AUTOSAR XML (schema 4-2-2)
package /STELLANTIS/EPT/ASWCs
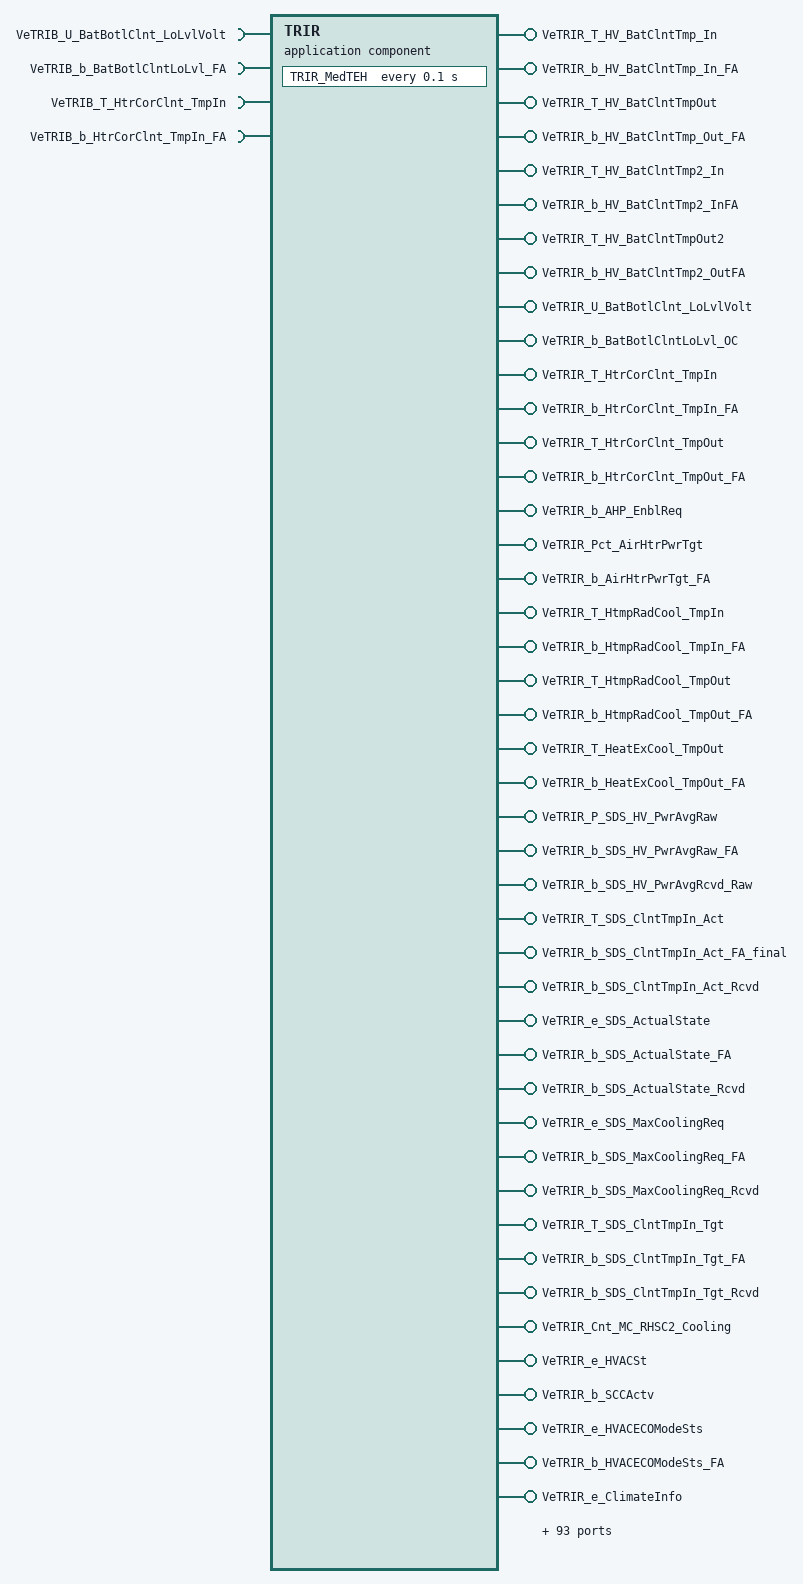
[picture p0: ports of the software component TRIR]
  application sw component type TRIR
    4 x require port, all with nonqueued-receiver-com-spec{data-element=Value, init-value=0}:
      VeTRIB_U_BatBotlClnt_LoLvlVolt: required-interface=VeTRIB_U_BatBotlClnt_LoLvlVolt
      VeTRIB_b_BatBotlClntLoLvl_FA: required-interface=VeTRIB_b_BatBotlClntLoLvl_FA
      VeTRIB_T_HtrCorClnt_TmpIn: required-interface=VeTRIB_T_HtrCorClnt_TmpIn
      VeTRIB_b_HtrCorClnt_TmpIn_FA: required-interface=VeTRIB_b_HtrCorClnt_TmpIn_FA
    137 x provide port:
      VeTRIR_T_HV_BatClntTmp_In: nonqueued-sender-com-spec{data-element=Value, init-value=0}, provided-interface=VeTRIR_T_HV_BatClntTmp_In
      VeTRIR_b_HV_BatClntTmp_In_FA: nonqueued-sender-com-spec{data-element=Value, init-value=0}, provided-interface=VeTRIR_b_HV_BatClntTmp_In_FA
      VeTRIR_T_HV_BatClntTmpOut: nonqueued-sender-com-spec{data-element=Value, init-value=0}, provided-interface=VeTRIR_T_HV_BatClntTmpOut
      VeTRIR_b_HV_BatClntTmp_Out_FA: nonqueued-sender-com-spec{data-element=Value, init-value=0}, provided-interface=VeTRIR_b_HV_BatClntTmp_Out_FA
      VeTRIR_T_HV_BatClntTmp2_In: nonqueued-sender-com-spec{data-element=Value, init-value=0}, provided-interface=VeTRIR_T_HV_BatClntTmp2_In
      VeTRIR_b_HV_BatClntTmp2_InFA: nonqueued-sender-com-spec{data-element=Value, init-value=0}, provided-interface=VeTRIR_b_HV_BatClntTmp2_InFA
      VeTRIR_T_HV_BatClntTmpOut2: nonqueued-sender-com-spec{data-element=Value, init-value=0}, provided-interface=VeTRIR_T_HV_BatClntTmpOut2
      VeTRIR_b_HV_BatClntTmp2_OutFA: nonqueued-sender-com-spec{data-element=Value, init-value=0}, provided-interface=VeTRIR_b_HV_BatClntTmp2_OutFA
      VeTRIR_U_BatBotlClnt_LoLvlVolt: nonqueued-sender-com-spec{data-element=Value, init-value=0}, provided-interface=VeTRIR_U_BatBotlClnt_LoLvlVolt
      VeTRIR_b_BatBotlClntLoLvl_OC: nonqueued-sender-com-spec{data-element=Value, init-value=0}, provided-interface=VeTRIR_b_BatBotlClntLoLvl_OC
      VeTRIR_T_HtrCorClnt_TmpIn: nonqueued-sender-com-spec{data-element=Value, init-value=0}, provided-interface=VeTRIR_T_HtrCorClnt_TmpIn
      VeTRIR_b_HtrCorClnt_TmpIn_FA: nonqueued-sender-com-spec{data-element=Value, init-value=0}, provided-interface=VeTRIR_b_HtrCorClnt_TmpIn_FA
      VeTRIR_T_HtrCorClnt_TmpOut: nonqueued-sender-com-spec{data-element=Value, init-value=0}, provided-interface=VeTRIR_T_HtrCorClnt_TmpOut
      VeTRIR_b_HtrCorClnt_TmpOut_FA: nonqueued-sender-com-spec{data-element=Value, init-value=0}, provided-interface=VeTRIR_b_HtrCorClnt_TmpOut_FA
      VeTRIR_b_AHP_EnblReq: nonqueued-sender-com-spec{data-element=Value, init-value=0}, provided-interface=VeTRIR_b_AHP_EnblReq
      VeTRIR_Pct_AirHtrPwrTgt: nonqueued-sender-com-spec{data-element=Value, init-value=0}, provided-interface=VeTRIR_Pct_AirHtrPwrTgt
      VeTRIR_b_AirHtrPwrTgt_FA: nonqueued-sender-com-spec{data-element=Value, init-value=0}, provided-interface=VeTRIR_b_AirHtrPwrTgt_FA
      VeTRIR_T_HtmpRadCool_TmpIn: nonqueued-sender-com-spec{data-element=Value, init-value=0}, provided-interface=VeTRIR_T_HtmpRadCool_TmpIn
      VeTRIR_b_HtmpRadCool_TmpIn_FA: nonqueued-sender-com-spec{data-element=Value, init-value=0}, provided-interface=VeTRIR_b_HtmpRadCool_TmpIn_FA
      VeTRIR_T_HtmpRadCool_TmpOut: nonqueued-sender-com-spec{data-element=Value, init-value=0}, provided-interface=VeTRIR_T_HtmpRadCool_TmpOut
      VeTRIR_b_HtmpRadCool_TmpOut_FA: nonqueued-sender-com-spec{data-element=Value, init-value=0}, provided-interface=VeTRIR_b_HtmpRadCool_TmpOut_FA
      VeTRIR_T_HeatExCool_TmpOut: nonqueued-sender-com-spec{data-element=Value, init-value=0}, provided-interface=VeTRIR_T_HeatExCool_TmpOut
      VeTRIR_b_HeatExCool_TmpOut_FA: nonqueued-sender-com-spec{data-element=Value, init-value=0}, provided-interface=VeTRIR_b_HeatExCool_TmpOut_FA
      VeTRIR_P_SDS_HV_PwrAvgRaw: nonqueued-sender-com-spec{data-element=Value, init-value=0}, provided-interface=VeTRIR_P_SDS_HV_PwrAvgRaw
      VeTRIR_b_SDS_HV_PwrAvgRaw_FA: nonqueued-sender-com-spec{data-element=Value, init-value=0}, provided-interface=VeTRIR_b_SDS_HV_PwrAvgRaw_FA
      VeTRIR_b_SDS_HV_PwrAvgRcvd_Raw: nonqueued-sender-com-spec{data-element=Value, init-value=0}, provided-interface=VeTRIR_b_SDS_HV_PwrAvgRcvd_Raw
      VeTRIR_T_SDS_ClntTmpIn_Act: nonqueued-sender-com-spec{data-element=Value, init-value=0}, provided-interface=VeTRIR_T_SDS_ClntTmpIn_Act
      VeTRIR_b_SDS_ClntTmpIn_Act_FA_final: nonqueued-sender-com-spec{data-element=Value, init-value=0}, provided-interface=VeTRIR_b_SDS_ClntTmpIn_Act_FA_final
      VeTRIR_b_SDS_ClntTmpIn_Act_Rcvd: nonqueued-sender-com-spec{data-element=Value, init-value=0}, provided-interface=VeTRIR_b_SDS_ClntTmpIn_Act_Rcvd
      VeTRIR_e_SDS_ActualState: nonqueued-sender-com-spec{data-element=Value, init-value=CeTRIR_e_SDS_OFF}, provided-interface=VeTRIR_e_SDS_ActualState
      VeTRIR_b_SDS_ActualState_FA: nonqueued-sender-com-spec{data-element=Value, init-value=0}, provided-interface=VeTRIR_b_SDS_ActualState_FA
      VeTRIR_b_SDS_ActualState_Rcvd: nonqueued-sender-com-spec{data-element=Value, init-value=0}, provided-interface=VeTRIR_b_SDS_ActualState_Rcvd
      VeTRIR_e_SDS_MaxCoolingReq: nonqueued-sender-com-spec{data-element=Value, init-value=CeTRIR_e_HCP_MaxCoolingNotRequested}, provided-interface=VeTRIR_e_SDS_MaxCoolingReq
      VeTRIR_b_SDS_MaxCoolingReq_FA: nonqueued-sender-com-spec{data-element=Value, init-value=0}, provided-interface=VeTRIR_b_SDS_MaxCoolingReq_FA
      VeTRIR_b_SDS_MaxCoolingReq_Rcvd: nonqueued-sender-com-spec{data-element=Value, init-value=0}, provided-interface=VeTRIR_b_SDS_MaxCoolingReq_Rcvd
      VeTRIR_T_SDS_ClntTmpIn_Tgt: nonqueued-sender-com-spec{data-element=Value, init-value=0}, provided-interface=VeTRIR_T_SDS_ClntTmpIn_Tgt
      VeTRIR_b_SDS_ClntTmpIn_Tgt_FA: nonqueued-sender-com-spec{data-element=Value, init-value=0}, provided-interface=VeTRIR_b_SDS_ClntTmpIn_Tgt_FA
      VeTRIR_b_SDS_ClntTmpIn_Tgt_Rcvd: nonqueued-sender-com-spec{data-element=Value, init-value=0}, provided-interface=VeTRIR_b_SDS_ClntTmpIn_Tgt_Rcvd
      VeTRIR_Cnt_MC_RHSC2_Cooling: nonqueued-sender-com-spec{data-element=Value, init-value=0}, provided-interface=VeTRIR_Cnt_MC_RHSC2_Cooling
      VeTRIR_e_HVACSt: nonqueued-sender-com-spec{data-element=Value, init-value=CeTRIR_e_HVAC_Off}, provided-interface=VeTRIR_e_HVACSt
      VeTRIR_b_SCCActv: nonqueued-sender-com-spec{data-element=Value, init-value=0}, provided-interface=VeTRIR_b_SCCActv
      VeTRIR_e_HVACECOModeSts: nonqueued-sender-com-spec{data-element=Value, init-value=CeTRIR_e_HVAC_ECO_OFF}, provided-interface=VeTRIR_e_HVACECOModeSts
      VeTRIR_b_HVACECOModeSts_FA: nonqueued-sender-com-spec{data-element=Value, init-value=0}, provided-interface=VeTRIR_b_HVACECOModeSts_FA
      VeTRIR_e_ClimateInfo: nonqueued-sender-com-spec{data-element=Value, init-value=CeTRIR_e_SPST_ON}, provided-interface=VeTRIR_e_ClimateInfo
      VeTRIR_b_ClimateInfo_FA: nonqueued-sender-com-spec{data-element=Value, init-value=0}, provided-interface=VeTRIR_b_ClimateInfo_FA
      VeTRIR_b_KeepHotColdButtonStatus: nonqueued-sender-com-spec{data-element=Value, init-value=0}, provided-interface=VeTRIR_b_KeepHotColdButtonStatus
      VeTRIR_b_KeepHotColdButtonStatus_FA: nonqueued-sender-com-spec{data-element=Value, init-value=0}, provided-interface=VeTRIR_b_KeepHotColdButtonStatus_FA
      VeTRIR_b_Comfort_EnblAct: nonqueued-sender-com-spec{data-element=Value, init-value=0}, provided-interface=VeTRIR_b_Comfort_EnblAct
      VeTRIR_b_Comfort_EnblAct_FA: nonqueued-sender-com-spec{data-element=Value, init-value=0}, provided-interface=VeTRIR_b_Comfort_EnblAct_FA
      VeTRIR_b_TrunkStatus: nonqueued-sender-com-spec{data-element=Value, init-value=0}, provided-interface=VeTRIR_b_TrunkStatus
      VeTRIR_b_TrunkStatus_FA: nonqueued-sender-com-spec{data-element=Value, init-value=0}, provided-interface=VeTRIR_b_TrunkStatus_FA
      VeTRIR_b_LoadShed: nonqueued-sender-com-spec{data-element=Value, init-value=0}, provided-interface=VeTRIR_b_LoadShed
      VeTRIR_b_LoadShed_FA: nonqueued-sender-com-spec{data-element=Value, init-value=0}, provided-interface=VeTRIR_b_LoadShed_FA
      VeTRIR_e_HSW_Sts: nonqueued-sender-com-spec{data-element=Value, init-value=CeTRIR_e_ModeOFF}, provided-interface=VeTRIR_e_HSW_Sts
      VeTRIR_b_HSW_Sts_FA: nonqueued-sender-com-spec{data-element=Value, init-value=0}, provided-interface=VeTRIR_b_HSW_Sts_FA
      VeTRIR_b_HSW_Fail: nonqueued-sender-com-spec{data-element=Value, init-value=0}, provided-interface=VeTRIR_b_HSW_Fail
      VeTRIR_e_FL_HS_Sts: nonqueued-sender-com-spec{data-element=Value, init-value=CeTRIR_e_ModeOFF}, provided-interface=VeTRIR_e_FL_HS_Sts
      VeTRIR_b_FL_HS_Fail: nonqueued-sender-com-spec{data-element=Value, init-value=0}, provided-interface=VeTRIR_b_FL_HS_Fail
      VeTRIR_e_FR_HS_Sts: nonqueued-sender-com-spec{data-element=Value, init-value=CeTRIR_e_ModeOFF}, provided-interface=VeTRIR_e_FR_HS_Sts
      VeTRIR_b_FR_HS_Fail: nonqueued-sender-com-spec{data-element=Value, init-value=0}, provided-interface=VeTRIR_b_FR_HS_Fail
      VeTRIR_e_RL_HS_Sts: nonqueued-sender-com-spec{data-element=Value, init-value=CeTRIR_e_ModeOFF}, provided-interface=VeTRIR_e_RL_HS_Sts
      VeTRIR_b_RL_HS_Fail: nonqueued-sender-com-spec{data-element=Value, init-value=0}, provided-interface=VeTRIR_b_RL_HS_Fail
      VeTRIR_e_RR_HS_Sts: nonqueued-sender-com-spec{data-element=Value, init-value=CeTRIR_e_ModeOFF}, provided-interface=VeTRIR_e_RR_HS_Sts
      VeTRIR_b_RR_HS_Fail: nonqueued-sender-com-spec{data-element=Value, init-value=0}, provided-interface=VeTRIR_b_RR_HS_Fail
      VeTRIR_e_FL_VS_Sts: nonqueued-sender-com-spec{data-element=Value, init-value=CeTRIR_e_ModeOFF}, provided-interface=VeTRIR_e_FL_VS_Sts
      VeTRIR_b_FL_VS_Fail: nonqueued-sender-com-spec{data-element=Value, init-value=0}, provided-interface=VeTRIR_b_FL_VS_Fail
      VeTRIR_e_FR_VS_Sts: nonqueued-sender-com-spec{data-element=Value, init-value=CeTRIR_e_ModeOFF}, provided-interface=VeTRIR_e_FR_VS_Sts
      VeTRIR_b_FR_VS_Fail: nonqueued-sender-com-spec{data-element=Value, init-value=0}, provided-interface=VeTRIR_b_FR_VS_Fail
      VeTRIR_e_RL_VS_Sts: nonqueued-sender-com-spec{data-element=Value, init-value=CeTRIR_e_ModeOFF}, provided-interface=VeTRIR_e_RL_VS_Sts
      VeTRIR_b_RL_VS_Fail: nonqueued-sender-com-spec{data-element=Value, init-value=0}, provided-interface=VeTRIR_b_RL_VS_Fail
      VeTRIR_e_RR_VS_Sts: nonqueued-sender-com-spec{data-element=Value, init-value=CeTRIR_e_ModeOFF}, provided-interface=VeTRIR_e_RR_VS_Sts
      VeTRIR_b_RR_VS_Fail: nonqueued-sender-com-spec{data-element=Value, init-value=0}, provided-interface=VeTRIR_b_RR_VS_Fail
      FsftTRIR_Pct_AirHtwPwrTgt: server-com-spec=FsftTRIR_Pct_AirHtwPwrTgt, provided-interface=FsftTRIR_Pct_AirHtwPwrTgt
      FsftTRIR_T_HV_BatClntTmp2Out: server-com-spec=FsftTRIR_T_HV_BatClntTmp2Out, provided-interface=FsftTRIR_T_HV_BatClntTmp2Out
      FsftTRIR_T_HV_BatClntTmp2_In: server-com-spec=FsftTRIR_T_HV_BatClntTmp2_In, provided-interface=FsftTRIR_T_HV_BatClntTmp2_In
      FsftTRIR_T_HV_BatClntTmpOut: server-com-spec=FsftTRIR_T_HV_BatClntTmpOut, provided-interface=FsftTRIR_T_HV_BatClntTmpOut
      FsftTRIR_T_HV_BatClntTmp_In: server-com-spec=FsftTRIR_T_HV_BatClntTmp_In, provided-interface=FsftTRIR_T_HV_BatClntTmp_In
      FsftTRIR_T_SDS_ClntTmpIn_Act: server-com-spec=FsftTRIR_T_SDS_ClntTmpIn_Act, provided-interface=FsftTRIR_T_SDS_ClntTmpIn_Act
      FsftTRIR_b_AHP_EnblReq: server-com-spec=FsftTRIR_b_AHP_EnblReq, provided-interface=FsftTRIR_b_AHP_EnblReq
      FsftTRIR_b_BCM_Comfort_EnblAct: server-com-spec=FsftTRIR_b_BCM_Comfort_EnblAct, provided-interface=FsftTRIR_b_BCM_Comfort_EnblAct
      FsftTRIR_b_ClimateInfo: server-com-spec=FsftTRIR_b_ClimateInfo, provided-interface=FsftTRIR_b_ClimateInfo
      FsftTRIR_b_ETM_KeepHotColdButtonStatus: server-com-spec=FsftTRIR_b_ETM_KeepHotColdButtonStatus, provided-interface=FsftTRIR_b_ETM_KeepHotColdButtonStatus
      FsftTRIR_b_HSW_Sts: server-com-spec=FsftTRIR_b_HSW_Sts, provided-interface=FsftTRIR_b_HSW_Sts
      FsftTRIR_b_HVACECOModeSts: server-com-spec=FsftTRIR_b_HVACECOModeSts, provided-interface=FsftTRIR_b_HVACECOModeSts
      FsftTRIR_b_HVACPrecCondSts: server-com-spec=FsftTRIR_b_HVACPrecCondSts, provided-interface=FsftTRIR_b_HVACPrecCondSts
      FsftTRIR_b_HeatExCool_TmpOut: server-com-spec=FsftTRIR_b_HeatExCool_TmpOut, provided-interface=FsftTRIR_b_HeatExCool_TmpOut
      FsftTRIR_b_HtmpRadCool_TmpIn: server-com-spec=FsftTRIR_b_HtmpRadCool_TmpIn, provided-interface=FsftTRIR_b_HtmpRadCool_TmpIn
      FsftTRIR_b_HtmpRadCool_TmpOut: server-com-spec=FsftTRIR_b_HtmpRadCool_TmpOut, provided-interface=FsftTRIR_b_HtmpRadCool_TmpOut
      FsftTRIR_b_HtrCorClnt_TmpOut: server-com-spec=FsftTRIR_b_HtrCorClnt_TmpOut, provided-interface=FsftTRIR_b_HtrCorClnt_TmpOut
      FsftTRIR_b_LoadShed: server-com-spec=FsftTRIR_b_LoadShed, provided-interface=FsftTRIR_b_LoadShed
      FsftTRIR_b_SCCActv: server-com-spec=FsftTRIR_b_SCCActv, provided-interface=FsftTRIR_b_SCCActv
      FsftTRIR_b_TrunkStatus: server-com-spec=FsftTRIR_b_TrunkStatus, provided-interface=FsftTRIR_b_TrunkStatus
      PokeTRIR_Cnt_MC_RHSC2_Cooling: server-com-spec{operation=PokeTRIR_Cnt_MC_RHSC2_Cooling, queue-length=1}, provided-interface=PokeTRIR_Cnt_MC_RHSC2_Cooling
      PokeTRIR_P_SDS_HV_PwrAvg: server-com-spec{operation=PokeTRIR_P_SDS_HV_PwrAvg, queue-length=1}, provided-interface=PokeTRIR_P_SDS_HV_PwrAvg
      PokeTRIR_Pct_AirHtwPwrTgt: server-com-spec{operation=PokeTRIR_Pct_AirHtwPwrTgt, queue-length=1}, provided-interface=PokeTRIR_Pct_AirHtwPwrTgt
      PokeTRIR_T_HV_BatClntTmp2_In: server-com-spec{operation=PokeTRIR_T_HV_BatClntTmp2_In, queue-length=1}, provided-interface=PokeTRIR_T_HV_BatClntTmp2_In
      PokeTRIR_T_HV_BatClntTmp2_Out: server-com-spec{operation=PokeTRIR_T_HV_BatClntTmp2_Out, queue-length=1}, provided-interface=PokeTRIR_T_HV_BatClntTmp2_Out
      PokeTRIR_T_HV_BatClntTmp_In: server-com-spec{operation=PokeTRIR_T_HV_BatClntTmp_In, queue-length=1}, provided-interface=PokeTRIR_T_HV_BatClntTmp_In
      PokeTRIR_T_HV_BatClntTmp_Out: server-com-spec{operation=PokeTRIR_T_HV_BatClntTmp_Out, queue-length=1}, provided-interface=PokeTRIR_T_HV_BatClntTmp_Out
      PokeTRIR_T_HeatExCool_TmpOut: server-com-spec{operation=PokeTRIR_T_HeatExCool_TmpOut, queue-length=1}, provided-interface=PokeTRIR_T_HeatExCool_TmpOut
      PokeTRIR_T_HtmpRadCool_TmpIn: server-com-spec{operation=PokeTRIR_T_HtmpRadCool_TmpIn, queue-length=1}, provided-interface=PokeTRIR_T_HtmpRadCool_TmpIn
      PokeTRIR_T_HtmpRadCool_TmpOut: server-com-spec{operation=PokeTRIR_T_HtmpRadCool_TmpOut, queue-length=1}, provided-interface=PokeTRIR_T_HtmpRadCool_TmpOut
      PokeTRIR_T_HtrCorClnt_TmpOut: server-com-spec{operation=PokeTRIR_T_HtrCorClnt_TmpOut, queue-length=1}, provided-interface=PokeTRIR_T_HtrCorClnt_TmpOut
      PokeTRIR_T_SDS_ClntTmpIn_Act: server-com-spec{operation=PokeTRIR_T_SDS_ClntTmpIn_Act, queue-length=1}, provided-interface=PokeTRIR_T_SDS_ClntTmpIn_Act
      PokeTRIR_T_SDS_ClntTmpIn_Tgt: server-com-spec{operation=PokeTRIR_T_SDS_ClntTmpIn_Tgt, queue-length=1}, provided-interface=PokeTRIR_T_SDS_ClntTmpIn_Tgt
      PokeTRIR_b_AHP_EnblReq: server-com-spec{operation=PokeTRIR_b_AHP_EnblReq, queue-length=1}, provided-interface=PokeTRIR_b_AHP_EnblReq
      PokeTRIR_b_BCM_Comfort_EnblAct: server-com-spec{operation=PokeTRIR_b_BCM_Comfort_EnblAct, queue-length=1}, provided-interface=PokeTRIR_b_BCM_Comfort_EnblAct
      PokeTRIR_b_ETM_KeepHotColdButtonStatus: server-com-spec{operation=PokeTRIR_b_ETM_KeepHotColdButtonStatus, queue-length=1}, provided-interface=PokeTRIR_b_ETM_KeepHotColdButtonStatus
      PokeTRIR_b_FL_HS_Fail: server-com-spec{operation=PokeTRIR_b_FL_HS_Fail, queue-length=1}, provided-interface=PokeTRIR_b_FL_HS_Fail
      PokeTRIR_b_FL_VS_Fail: server-com-spec{operation=PokeTRIR_b_FL_VS_Fail, queue-length=1}, provided-interface=PokeTRIR_b_FL_VS_Fail
      PokeTRIR_b_FR_HS_Fail: server-com-spec{operation=PokeTRIR_b_FR_HS_Fail, queue-length=1}, provided-interface=PokeTRIR_b_FR_HS_Fail
      PokeTRIR_b_FR_VS_Fail: server-com-spec{operation=PokeTRIR_b_FR_VS_Fail, queue-length=1}, provided-interface=PokeTRIR_b_FR_VS_Fail
      PokeTRIR_b_HSW_Fail: server-com-spec{operation=PokeTRIR_b_HSW_Fail, queue-length=1}, provided-interface=PokeTRIR_b_HSW_Fail
      PokeTRIR_b_LoadShed: server-com-spec{operation=PokeTRIR_b_LoadShed, queue-length=1}, provided-interface=PokeTRIR_b_LoadShed
      PokeTRIR_b_RL_HS_Fail: server-com-spec{operation=PokeTRIR_b_RL_HS_Fail, queue-length=1}, provided-interface=PokeTRIR_b_RL_HS_Fail
      PokeTRIR_b_RL_VS_Fail: server-com-spec{operation=PokeTRIR_b_RL_VS_Fail, queue-length=1}, provided-interface=PokeTRIR_b_RL_VS_Fail
      PokeTRIR_b_RR_HS_Fail: server-com-spec{operation=PokeTRIR_b_RR_HS_Fail, queue-length=1}, provided-interface=PokeTRIR_b_RR_HS_Fail
      PokeTRIR_b_RR_VS_Fail: server-com-spec{operation=PokeTRIR_b_RR_VS_Fail, queue-length=1}, provided-interface=PokeTRIR_b_RR_VS_Fail
      PokeTRIR_b_SCCActv: server-com-spec{operation=PokeTRIR_b_SCCActv, queue-length=1}, provided-interface=PokeTRIR_b_SCCActv
      PokeTRIR_b_TrunkStatus: server-com-spec{operation=PokeTRIR_b_TrunkStatus, queue-length=1}, provided-interface=PokeTRIR_b_TrunkStatus
      PokeTRIR_e_ClimateInfo: server-com-spec{operation=PokeTRIR_e_ClimateInfo, queue-length=1}, provided-interface=PokeTRIR_e_ClimateInfo
      PokeTRIR_e_FL_HS_Sts: server-com-spec{operation=PokeTRIR_e_FL_HS_Sts, queue-length=1}, provided-interface=PokeTRIR_e_FL_HS_Sts
      PokeTRIR_e_FL_VS_Sts: server-com-spec{operation=PokeTRIR_e_FL_VS_Sts, queue-length=1}, provided-interface=PokeTRIR_e_FL_VS_Sts
      PokeTRIR_e_FR_HS_Sts: server-com-spec{operation=PokeTRIR_e_FR_HS_Sts, queue-length=1}, provided-interface=PokeTRIR_e_FR_HS_Sts
      PokeTRIR_e_FR_VS_Sts: server-com-spec{operation=PokeTRIR_e_FR_VS_Sts, queue-length=1}, provided-interface=PokeTRIR_e_FR_VS_Sts
      PokeTRIR_e_HSW_Sts: server-com-spec{operation=PokeTRIR_e_HSW_Sts, queue-length=1}, provided-interface=PokeTRIR_e_HSW_Sts
      PokeTRIR_e_HVACECOModeSts: server-com-spec{operation=PokeTRIR_e_HVACECOModeSts, queue-length=1}, provided-interface=PokeTRIR_e_HVACECOModeSts
      PokeTRIR_e_HVACPrecCondSts: server-com-spec{operation=PokeTRIR_e_HVACPrecCondSts, queue-length=1}, provided-interface=PokeTRIR_e_HVACPrecCondSts
      PokeTRIR_e_RL_HS_Sts: server-com-spec{operation=PokeTRIR_e_RL_HS_Sts, queue-length=1}, provided-interface=PokeTRIR_e_RL_HS_Sts
      PokeTRIR_e_RL_VS_Sts: server-com-spec{operation=PokeTRIR_e_RL_VS_Sts, queue-length=1}, provided-interface=PokeTRIR_e_RL_VS_Sts
      PokeTRIR_e_RR_HS_Sts: server-com-spec{operation=PokeTRIR_e_RR_HS_Sts, queue-length=1}, provided-interface=PokeTRIR_e_RR_HS_Sts
      PokeTRIR_e_RR_VS_Sts: server-com-spec{operation=PokeTRIR_e_RR_VS_Sts, queue-length=1}, provided-interface=PokeTRIR_e_RR_VS_Sts
      PokeTRIR_e_SDS_ActualState: server-com-spec{operation=PokeTRIR_e_SDS_ActualState, queue-length=1}, provided-interface=PokeTRIR_e_SDS_ActualState
      PokeTRIR_e_SDS_MaxCoolingReq: server-com-spec{operation=PokeTRIR_e_SDS_MaxCoolingReq, queue-length=1}, provided-interface=PokeTRIR_e_SDS_MaxCoolingReq
      TmotTRIR_T_SDS_ClntTmpIn_Act: server-com-spec=TmotTRIR_T_SDS_ClntTmpIn_Act, provided-interface=TmotTRIR_T_SDS_ClntTmpIn_Act
      TmotTRIR_b_HVACPrecCondSts: server-com-spec=TmotTRIR_b_HVACPrecCondSts, provided-interface=TmotTRIR_b_HVACPrecCondSts
      TmotTRIR_b_SCCActv: server-com-spec=TmotTRIR_b_SCCActv, provided-interface=TmotTRIR_b_SCCActv
    behavior IB_TRIR: data-type-mapping=msADTtoIDTMapping, handle-termination-and-restart=NO-SUPPORT
      timing event Event_MedTEH: start-on-event=TRIR_MedTEH, period=0.1
      65 x operation invoked event:
        Event_FsftTRIR_Pct_AirHtwPwrTgt: start-on-event=FsftTRIR_Pct_AirHtwPwrTgt, operation=FsftTRIR_Pct_AirHtwPwrTgt.FsftTRIR_Pct_AirHtwPwrTgt
        Event_FsftTRIR_T_HV_BatClntTmp2Out: start-on-event=FsftTRIR_T_HV_BatClntTmp2Out, operation=FsftTRIR_T_HV_BatClntTmp2Out.FsftTRIR_T_HV_BatClntTmp2Out
        Event_FsftTRIR_T_HV_BatClntTmp2_In: start-on-event=FsftTRIR_T_HV_BatClntTmp2_In, operation=FsftTRIR_T_HV_BatClntTmp2_In.FsftTRIR_T_HV_BatClntTmp2_In
        Event_FsftTRIR_T_HV_BatClntTmpOut: start-on-event=FsftTRIR_T_HV_BatClntTmpOut, operation=FsftTRIR_T_HV_BatClntTmpOut.FsftTRIR_T_HV_BatClntTmpOut
        Event_FsftTRIR_T_HV_BatClntTmp_In: start-on-event=FsftTRIR_T_HV_BatClntTmp_In, operation=FsftTRIR_T_HV_BatClntTmp_In.FsftTRIR_T_HV_BatClntTmp_In
        Event_FsftTRIR_T_SDS_ClntTmpIn_Act: start-on-event=FsftTRIR_T_SDS_ClntTmpIn_Act, operation=FsftTRIR_T_SDS_ClntTmpIn_Act.FsftTRIR_T_SDS_ClntTmpIn_Act
        Event_FsftTRIR_b_AHP_EnblReq: start-on-event=FsftTRIR_b_AHP_EnblReq, operation=FsftTRIR_b_AHP_EnblReq.FsftTRIR_b_AHP_EnblReq
        Event_FsftTRIR_b_BCM_Comfort_EnblAct: start-on-event=FsftTRIR_b_BCM_Comfort_EnblAct, operation=FsftTRIR_b_BCM_Comfort_EnblAct.FsftTRIR_b_BCM_Comfort_EnblAct
        Event_FsftTRIR_b_ClimateInfo: start-on-event=FsftTRIR_b_ClimateInfo, operation=FsftTRIR_b_ClimateInfo.FsftTRIR_b_ClimateInfo
        Event_FsftTRIR_b_ETM_KeepHotColdButtonStatus: start-on-event=FsftTRIR_b_ETM_KeepHotColdButtonStatus, operation=FsftTRIR_b_ETM_KeepHotColdButtonStatus.FsftTRIR_b_ETM_KeepHotColdButtonStatus
        Event_FsftTRIR_b_HSW_Sts: start-on-event=FsftTRIR_b_HSW_Sts, operation=FsftTRIR_b_HSW_Sts.FsftTRIR_b_HSW_Sts
        Event_FsftTRIR_b_HVACECOModeSts: start-on-event=FsftTRIR_b_HVACECOModeSts, operation=FsftTRIR_b_HVACECOModeSts.FsftTRIR_b_HVACECOModeSts
        Event_FsftTRIR_b_HVACPrecCondSts: start-on-event=FsftTRIR_b_HVACPrecCondSts, operation=FsftTRIR_b_HVACPrecCondSts.FsftTRIR_b_HVACPrecCondSts
        Event_FsftTRIR_b_HeatExCool_TmpOut: start-on-event=FsftTRIR_b_HeatExCool_TmpOut, operation=FsftTRIR_b_HeatExCool_TmpOut.FsftTRIR_b_HeatExCool_TmpOut
        Event_FsftTRIR_b_HtmpRadCool_TmpIn: start-on-event=FsftTRIR_b_HtmpRadCool_TmpIn, operation=FsftTRIR_b_HtmpRadCool_TmpIn.FsftTRIR_b_HtmpRadCool_TmpIn
        Event_FsftTRIR_b_HtmpRadCool_TmpOut: start-on-event=FsftTRIR_b_HtmpRadCool_TmpOut, operation=FsftTRIR_b_HtmpRadCool_TmpOut.FsftTRIR_b_HtmpRadCool_TmpOut
        Event_FsftTRIR_b_HtrCorClnt_TmpOut: start-on-event=FsftTRIR_b_HtrCorClnt_TmpOut, operation=FsftTRIR_b_HtrCorClnt_TmpOut.FsftTRIR_b_HtrCorClnt_TmpOut
        Event_FsftTRIR_b_LoadShed: start-on-event=FsftTRIR_b_LoadShed, operation=FsftTRIR_b_LoadShed.FsftTRIR_b_LoadShed
        Event_FsftTRIR_b_SCCActv: start-on-event=FsftTRIR_b_SCCActv, operation=FsftTRIR_b_SCCActv.FsftTRIR_b_SCCActv
        Event_FsftTRIR_b_TrunkStatus: start-on-event=FsftTRIR_b_TrunkStatus, operation=FsftTRIR_b_TrunkStatus.FsftTRIR_b_TrunkStatus
        Event_PokeTRIR_Cnt_MC_RHSC2_Cooling: start-on-event=PokeTRIR_Cnt_MC_RHSC2_Cooling, operation=PokeTRIR_Cnt_MC_RHSC2_Cooling.PokeTRIR_Cnt_MC_RHSC2_Cooling
        Event_PokeTRIR_P_SDS_HV_PwrAvg: start-on-event=PokeTRIR_P_SDS_HV_PwrAvg, operation=PokeTRIR_P_SDS_HV_PwrAvg.PokeTRIR_P_SDS_HV_PwrAvg
        Event_PokeTRIR_Pct_AirHtwPwrTgt: start-on-event=PokeTRIR_Pct_AirHtwPwrTgt, operation=PokeTRIR_Pct_AirHtwPwrTgt.PokeTRIR_Pct_AirHtwPwrTgt
        Event_PokeTRIR_T_HV_BatClntTmp2_In: start-on-event=PokeTRIR_T_HV_BatClntTmp2_In, operation=PokeTRIR_T_HV_BatClntTmp2_In.PokeTRIR_T_HV_BatClntTmp2_In
        Event_PokeTRIR_T_HV_BatClntTmp2_Out: start-on-event=PokeTRIR_T_HV_BatClntTmp2_Out, operation=PokeTRIR_T_HV_BatClntTmp2_Out.PokeTRIR_T_HV_BatClntTmp2_Out
        Event_PokeTRIR_T_HV_BatClntTmp_In: start-on-event=PokeTRIR_T_HV_BatClntTmp_In, operation=PokeTRIR_T_HV_BatClntTmp_In.PokeTRIR_T_HV_BatClntTmp_In
        Event_PokeTRIR_T_HV_BatClntTmp_Out: start-on-event=PokeTRIR_T_HV_BatClntTmp_Out, operation=PokeTRIR_T_HV_BatClntTmp_Out.PokeTRIR_T_HV_BatClntTmp_Out
        Event_PokeTRIR_T_HeatExCool_TmpOut: start-on-event=PokeTRIR_T_HeatExCool_TmpOut, operation=PokeTRIR_T_HeatExCool_TmpOut.PokeTRIR_T_HeatExCool_TmpOut
        Event_PokeTRIR_T_HtmpRadCool_TmpIn: start-on-event=PokeTRIR_T_HtmpRadCool_TmpIn, operation=PokeTRIR_T_HtmpRadCool_TmpIn.PokeTRIR_T_HtmpRadCool_TmpIn
        Event_PokeTRIR_T_HtmpRadCool_TmpOut: start-on-event=PokeTRIR_T_HtmpRadCool_TmpOut, operation=PokeTRIR_T_HtmpRadCool_TmpOut.PokeTRIR_T_HtmpRadCool_TmpOut
        Event_PokeTRIR_T_HtrCorClnt_TmpOut: start-on-event=PokeTRIR_T_HtrCorClnt_TmpOut, operation=PokeTRIR_T_HtrCorClnt_TmpOut.PokeTRIR_T_HtrCorClnt_TmpOut
        Event_PokeTRIR_T_SDS_ClntTmpIn_Act: start-on-event=PokeTRIR_T_SDS_ClntTmpIn_Act, operation=PokeTRIR_T_SDS_ClntTmpIn_Act.PokeTRIR_T_SDS_ClntTmpIn_Act
        Event_PokeTRIR_T_SDS_ClntTmpIn_Tgt: start-on-event=PokeTRIR_T_SDS_ClntTmpIn_Tgt, operation=PokeTRIR_T_SDS_ClntTmpIn_Tgt.PokeTRIR_T_SDS_ClntTmpIn_Tgt
        Event_PokeTRIR_b_AHP_EnblReq: start-on-event=PokeTRIR_b_AHP_EnblReq, operation=PokeTRIR_b_AHP_EnblReq.PokeTRIR_b_AHP_EnblReq
        Event_PokeTRIR_b_BCM_Comfort_EnblAct: start-on-event=PokeTRIR_b_BCM_Comfort_EnblAct, operation=PokeTRIR_b_BCM_Comfort_EnblAct.PokeTRIR_b_BCM_Comfort_EnblAct
        Event_PokeTRIR_b_ETM_KeepHotColdButtonStatus: start-on-event=PokeTRIR_b_ETM_KeepHotColdButtonStatus, operation=PokeTRIR_b_ETM_KeepHotColdButtonStatus.PokeTRIR_b_ETM_KeepHotColdButtonStatus
        Event_PokeTRIR_b_FL_HS_Fail: start-on-event=PokeTRIR_b_FL_HS_Fail, operation=PokeTRIR_b_FL_HS_Fail.PokeTRIR_b_FL_HS_Fail
        Event_PokeTRIR_b_FL_VS_Fail: start-on-event=PokeTRIR_b_FL_VS_Fail, operation=PokeTRIR_b_FL_VS_Fail.PokeTRIR_b_FL_VS_Fail
        Event_PokeTRIR_b_FR_HS_Fail: start-on-event=PokeTRIR_b_FR_HS_Fail, operation=PokeTRIR_b_FR_HS_Fail.PokeTRIR_b_FR_HS_Fail
        Event_PokeTRIR_b_FR_VS_Fail: start-on-event=PokeTRIR_b_FR_VS_Fail, operation=PokeTRIR_b_FR_VS_Fail.PokeTRIR_b_FR_VS_Fail
        Event_PokeTRIR_b_HSW_Fail: start-on-event=PokeTRIR_b_HSW_Fail, operation=PokeTRIR_b_HSW_Fail.PokeTRIR_b_HSW_Fail
        Event_PokeTRIR_b_LoadShed: start-on-event=PokeTRIR_b_LoadShed, operation=PokeTRIR_b_LoadShed.PokeTRIR_b_LoadShed
        Event_PokeTRIR_b_RL_HS_Fail: start-on-event=PokeTRIR_b_RL_HS_Fail, operation=PokeTRIR_b_RL_HS_Fail.PokeTRIR_b_RL_HS_Fail
        Event_PokeTRIR_b_RL_VS_Fail: start-on-event=PokeTRIR_b_RL_VS_Fail, operation=PokeTRIR_b_RL_VS_Fail.PokeTRIR_b_RL_VS_Fail
        Event_PokeTRIR_b_RR_HS_Fail: start-on-event=PokeTRIR_b_RR_HS_Fail, operation=PokeTRIR_b_RR_HS_Fail.PokeTRIR_b_RR_HS_Fail
        Event_PokeTRIR_b_RR_VS_Fail: start-on-event=PokeTRIR_b_RR_VS_Fail, operation=PokeTRIR_b_RR_VS_Fail.PokeTRIR_b_RR_VS_Fail
        Event_PokeTRIR_b_SCCActv: start-on-event=PokeTRIR_b_SCCActv, operation=PokeTRIR_b_SCCActv.PokeTRIR_b_SCCActv
        Event_PokeTRIR_b_TrunkStatus: start-on-event=PokeTRIR_b_TrunkStatus, operation=PokeTRIR_b_TrunkStatus.PokeTRIR_b_TrunkStatus
        Event_PokeTRIR_e_ClimateInfo: start-on-event=PokeTRIR_e_ClimateInfo, operation=PokeTRIR_e_ClimateInfo.PokeTRIR_e_ClimateInfo
        Event_PokeTRIR_e_FL_HS_Sts: start-on-event=PokeTRIR_e_FL_HS_Sts, operation=PokeTRIR_e_FL_HS_Sts.PokeTRIR_e_FL_HS_Sts
        Event_PokeTRIR_e_FL_VS_Sts: start-on-event=PokeTRIR_e_FL_VS_Sts, operation=PokeTRIR_e_FL_VS_Sts.PokeTRIR_e_FL_VS_Sts
        Event_PokeTRIR_e_FR_HS_Sts: start-on-event=PokeTRIR_e_FR_HS_Sts, operation=PokeTRIR_e_FR_HS_Sts.PokeTRIR_e_FR_HS_Sts
        Event_PokeTRIR_e_FR_VS_Sts: start-on-event=PokeTRIR_e_FR_VS_Sts, operation=PokeTRIR_e_FR_VS_Sts.PokeTRIR_e_FR_VS_Sts
        Event_PokeTRIR_e_HSW_Sts: start-on-event=PokeTRIR_e_HSW_Sts, operation=PokeTRIR_e_HSW_Sts.PokeTRIR_e_HSW_Sts
        Event_PokeTRIR_e_HVACECOModeSts: start-on-event=PokeTRIR_e_HVACECOModeSts, operation=PokeTRIR_e_HVACECOModeSts.PokeTRIR_e_HVACECOModeSts
        Event_PokeTRIR_e_HVACPrecCondSts: start-on-event=PokeTRIR_e_HVACPrecCondSts, operation=PokeTRIR_e_HVACPrecCondSts.PokeTRIR_e_HVACPrecCondSts
        Event_PokeTRIR_e_RL_HS_Sts: start-on-event=PokeTRIR_e_RL_HS_Sts, operation=PokeTRIR_e_RL_HS_Sts.PokeTRIR_e_RL_HS_Sts
        Event_PokeTRIR_e_RL_VS_Sts: start-on-event=PokeTRIR_e_RL_VS_Sts, operation=PokeTRIR_e_RL_VS_Sts.PokeTRIR_e_RL_VS_Sts
        Event_PokeTRIR_e_RR_HS_Sts: start-on-event=PokeTRIR_e_RR_HS_Sts, operation=PokeTRIR_e_RR_HS_Sts.PokeTRIR_e_RR_HS_Sts
        Event_PokeTRIR_e_RR_VS_Sts: start-on-event=PokeTRIR_e_RR_VS_Sts, operation=PokeTRIR_e_RR_VS_Sts.PokeTRIR_e_RR_VS_Sts
        Event_PokeTRIR_e_SDS_ActualState: start-on-event=PokeTRIR_e_SDS_ActualState, operation=PokeTRIR_e_SDS_ActualState.PokeTRIR_e_SDS_ActualState
        Event_PokeTRIR_e_SDS_MaxCoolingReq: start-on-event=PokeTRIR_e_SDS_MaxCoolingReq, operation=PokeTRIR_e_SDS_MaxCoolingReq.PokeTRIR_e_SDS_MaxCoolingReq
        Event_TmotTRIR_T_SDS_ClntTmpIn_Act: start-on-event=TmotTRIR_T_SDS_ClntTmpIn_Act, operation=TmotTRIR_T_SDS_ClntTmpIn_Act.TmotTRIR_T_SDS_ClntTmpIn_Act
        Event_TmotTRIR_b_HVACPrecCondSts: start-on-event=TmotTRIR_b_HVACPrecCondSts, operation=TmotTRIR_b_HVACPrecCondSts.TmotTRIR_b_HVACPrecCondSts
        Event_TmotTRIR_b_SCCActv: start-on-event=TmotTRIR_b_SCCActv, operation=TmotTRIR_b_SCCActv.TmotTRIR_b_SCCActv
      init event Event_TRIR_ac_Init: start-on-event=TRIR_ac_Init
      init event Event_PwrOn: start-on-event=TRIR_PwrOn
      explicit-inter-runnable-variables:
        73 x data, all with category=VALUE, sw-calibration-access=READ-ONLY:
          HV_BatClntTmp_In_AD_Prev_IRV: type=Float, init-value=0
          VeTRIR_T_HV_BatClntTmp_In_write_IRV: type=Float, init-value=0
          VeTRIR_b_HV_BatClntTmp_InFA_write_IRV: type=Boolean, init-value=0
          HV_BatClntTmpOut_AD_Prev_IRV: type=Float, init-value=0
          VeTRIR_T_HV_BatClntTmp_Out_write_IRV: type=Float, init-value=0
          VeTRIR_b_HV_BatClntTmpOutFA_write_IRV: type=Boolean, init-value=0
          VeTRIR_T_HV_BatClntTmp2_In_write_IRV: type=Float, init-value=0
          HV_BatClntTmp2_In_AD_Prev_IRV: type=Float, init-value=0
          VeTRIR_T_HV_BatClntTmp2_Out_write_IRV: type=Float, init-value=0
          HV_BatClntTmpOut2_AD_Prev_IRV: type=Float, init-value=0
          VeTRIR_b_HV_BatClntTmp2_InFA_write_IRV: type=Boolean, init-value=0
          VeTRIR_b_HV_BatClntTmp2OutFA_write_IRV: type=Boolean, init-value=0
          VeTRIR_Pct_AirHtwPwrTgt_write_IRV: type=Float, init-value=0
          VeTRIR_b_AirHtwPwrTgtFA_write_IRV: type=Boolean, init-value=0
          VeTRIR_b_AHP_EnblReqFA_write_IRV: type=Boolean, init-value=0
          VeTRIR_b_AHP_EnblReq_write_IRV: type=Boolean, init-value=0
          VeTRIR_T_HtrCorClnt_TmpOut_write_IRV: type=Float, init-value=0
          VeTRIR_b_HtrCorClnt_TmpOutFA_write_IRV: type=Boolean, init-value=0
          VeTRIR_T_HtmpRadCool_TmpIn_write_IRV: type=Float, init-value=0
          VeTRIR_b_HtmpRadCool_TmpInFA_write_IRV: type=Boolean, init-value=0
          VeTRIR_T_HtmpRadCool_TmpOut_write_IRV: type=Float, init-value=0
          VeTRIR_b_HtmpRadCool_TmpOutFA_write_IRV: type=Boolean, init-value=0
          VeTRIR_T_HeatExCool_TmpOut_write_IRV: type=Float, init-value=0
          VeTRIR_b_HeatExCool_TmpOutFA_write_IRV: type=Boolean, init-value=0
          VeTRIR_e_HSW_Sts_write_IRV: type=TeTRIR_e_ClimateSts, init-value=CeTRIR_e_ModeOFF
          VeTRIR_b_HSW_StsFA_write_IRV: type=Boolean, init-value=0
          VeTRIR_b_HSW_Fail_write_IRV: type=Boolean, init-value=0
          VeTRIR_e_FL_HS_Sts_write_IRV: type=TeTRIR_e_ClimateSts, init-value=CeTRIR_e_ModeOFF
          VeTRIR_b_FL_HS_Fail_write_IRV: type=Boolean, init-value=0
          VeTRIR_e_FR_HS_Sts_write_IRV: type=TeTRIR_e_ClimateSts, init-value=CeTRIR_e_ModeOFF
          VeTRIR_b_FR_HS_Fail_write_IRV: type=Boolean, init-value=0
          VeTRIR_e_RL_HS_Sts_write_IRV: type=TeTRIR_e_ClimateSts, init-value=CeTRIR_e_ModeOFF
          VeTRIR_b_RL_HS_Fail_write_IRV: type=Boolean, init-value=0
          VeTRIR_e_RR_HS_Sts_write_IRV: type=TeTRIR_e_ClimateSts, init-value=CeTRIR_e_ModeOFF
          VeTRIR_b_RR_HS_Fail_write_IRV: type=Boolean, init-value=0
          VeTRIR_e_FL_VS_Sts_write_IRV: type=TeTRIR_e_ClimateSts, init-value=CeTRIR_e_ModeOFF
          VeTRIR_b_FL_VS_Fail_write_IRV: type=Boolean, init-value=0
          VeTRIR_e_FR_VS_Sts_write_IRV: type=TeTRIR_e_ClimateSts, init-value=CeTRIR_e_ModeOFF
          VeTRIR_b_FR_VS_Fail_write_IRV: type=Boolean, init-value=0
          VeTRIR_e_RL_VS_Sts_write_IRV: type=TeTRIR_e_ClimateSts, init-value=CeTRIR_e_ModeOFF
          VeTRIR_b_RL_VS_Fail_write_IRV: type=Boolean, init-value=0
          VeTRIR_e_RR_VS_Sts_write_IRV: type=TeTRIR_e_ClimateSts, init-value=CeTRIR_e_ModeOFF
          VeTRIR_b_RR_VS_Fail_write_IRV: type=Boolean, init-value=0
          VeTRIR_P_SDS_HV_PwrAvg_write_IRV: type=Float, init-value=0
          VeTRIR_b_SDS_HV_PwrAvgFA_write_IRV: type=Boolean, init-value=0
          VeTRIR_b_SDS_HV_PwrAvgSgnl_Rcvd_write_IRV: type=Boolean, init-value=0
          VeTRIR_T_SDS_ClntTmpIn_Act_write_IRV: type=Float, init-value=0
          VeTRIR_b_SDS_ClntTmpIn_ActFA_write_IRV: type=Boolean, init-value=0
          VeTRIR_b_SDS_ClntTmpIn_ActSgnl_Rcvd_write_IRV: type=Boolean, init-value=0
          VeTRIR_T_SDS_ClntTmpIn_Tgt_write_IRV: type=Float, init-value=0
          VeTRIR_b_SDS_ClntTmpIn_TgtFA_write_IRV: type=Boolean, init-value=0
          VeTRIR_b_SDS_ClntTmpIn_TgtSgnl_Rcvd_write_IRV: type=Boolean, init-value=0
          VeTRIR_e_SDS_ActualState_write_IRV: type=TeTRIR_e_SDS_ActualState, init-value=CeTRIR_e_SDS_OFF
          VeTRIR_b_SDS_ActualStateFA_write_IRV: type=Boolean, init-value=0
          VeTRIR_b_SDS_ActualStateSgnl_Rcvd_write_IRV: type=Boolean, init-value=0
          VeTRIR_e_SDS_MaxCoolingReq_write_IRV: type=TeTRIR_e_HCP_MaxCoolingReq, init-value=CeTRIR_e_HCP_MaxCoolingNotRequested
          VeTRIR_b_SDS_MaxCoolingReqFA_write_IRV: type=Boolean, init-value=0
          VeTRIR_b_SDS_MaxCoolingReqSgnl_Rcvd_write_IRV: type=Boolean, init-value=0
          VeTRIR_Cnt_MC_RHSC2_Cooling_write_IRV: type=SInt16, init-value=0
          VeTRIR_b_SCCActv_write_IRV: type=Boolean, init-value=0
          VeTRIR_e_HVACPrecCondSts_write_IRV: type=TeTRIR_e_HVAC_State, init-value=CeTRIR_e_HVAC_Off
          VeTRIR_e_HVACECOModeSts_write_IRV: type=TeTRIR_e_HVAC_ECO_State, init-value=CeTRIR_e_HVAC_ECO_OFF
          VeTRIR_b_HVACECOModeStsFA_write_IRV: type=Boolean, init-value=0
          VeTRIR_e_ClimateInfo_write_IRV: type=TeTRIR_e_ClimateInfo, init-value=CeTRIR_e_SPST_ON
          VeTRIR_b_ClimateInfoFA_write_IRV: type=Boolean, init-value=0
          VeTRIR_b_ETM_KeepHotColdButtonStatus_write_IRV: type=Boolean, init-value=0
          VeTRIR_b_ETM_KeepHotColdButtonStatusFA_write_IRV: type=Boolean, init-value=0
          VeTRIR_b_BCM_Comfort_EnblAct_write_IRV: type=Boolean, init-value=0
          VeTRIR_b_BCM_Comfort_EnblActFA_write_IRV: type=Boolean, init-value=0
          VeTRIR_b_TrunkStatus_write_IRV: type=Boolean, init-value=0
          VeTRIR_b_TrunkStatusFA_write_IRV: type=Boolean, init-value=0
          VeTRIR_b_LoadShed_write_IRV: type=Boolean, init-value=0
          VeTRIR_b_LoadShedFA_write_IRV: type=Boolean, init-value=0
      68 x runnable:
        TRIR_ac_Init
          data-send-points:
            14 x access:
              OUT_VeTRIR_e_SDS_ActualState_Value: accessed-variable=VeTRIR_e_SDS_ActualState.Value
              OUT_VeTRIR_e_SDS_MaxCoolingReq_Value: accessed-variable=VeTRIR_e_SDS_MaxCoolingReq.Value
              OUT_VeTRIR_e_HVACSt_Value: accessed-variable=VeTRIR_e_HVACSt.Value
              OUT_VeTRIR_e_HVACECOModeSts_Value: accessed-variable=VeTRIR_e_HVACECOModeSts.Value
              OUT_VeTRIR_e_ClimateInfo_Value: accessed-variable=VeTRIR_e_ClimateInfo.Value
              OUT_VeTRIR_e_HSW_Sts_Value: accessed-variable=VeTRIR_e_HSW_Sts.Value
              OUT_VeTRIR_e_FL_HS_Sts_Value: accessed-variable=VeTRIR_e_FL_HS_Sts.Value
              OUT_VeTRIR_e_FR_HS_Sts_Value: accessed-variable=VeTRIR_e_FR_HS_Sts.Value
              OUT_VeTRIR_e_RL_HS_Sts_Value: accessed-variable=VeTRIR_e_RL_HS_Sts.Value
              OUT_VeTRIR_e_RR_HS_Sts_Value: accessed-variable=VeTRIR_e_RR_HS_Sts.Value
              OUT_VeTRIR_e_FL_VS_Sts_Value: accessed-variable=VeTRIR_e_FL_VS_Sts.Value
              OUT_VeTRIR_e_FR_VS_Sts_Value: accessed-variable=VeTRIR_e_FR_VS_Sts.Value
              OUT_VeTRIR_e_RL_VS_Sts_Value: accessed-variable=VeTRIR_e_RL_VS_Sts.Value
              OUT_VeTRIR_e_RR_VS_Sts_Value: accessed-variable=VeTRIR_e_RR_VS_Sts.Value
        TRIR_PwrOn
          data-send-points:
            72 x access:
              OUT_VeTRIR_T_HV_BatClntTmp_In_Value: accessed-variable=VeTRIR_T_HV_BatClntTmp_In.Value
              OUT_VeTRIR_b_HV_BatClntTmp_In_FA_Value: accessed-variable=VeTRIR_b_HV_BatClntTmp_In_FA.Value
              OUT_VeTRIR_T_HV_BatClntTmpOut_Value: accessed-variable=VeTRIR_T_HV_BatClntTmpOut.Value
              OUT_VeTRIR_b_HV_BatClntTmp_Out_FA_Value: accessed-variable=VeTRIR_b_HV_BatClntTmp_Out_FA.Value
              OUT_VeTRIR_T_HV_BatClntTmp2_In_Value: accessed-variable=VeTRIR_T_HV_BatClntTmp2_In.Value
              OUT_VeTRIR_b_HV_BatClntTmp2_InFA_Value: accessed-variable=VeTRIR_b_HV_BatClntTmp2_InFA.Value
              OUT_VeTRIR_T_HV_BatClntTmpOut2_Value: accessed-variable=VeTRIR_T_HV_BatClntTmpOut2.Value
              OUT_VeTRIR_b_HV_BatClntTmp2_OutFA_Value: accessed-variable=VeTRIR_b_HV_BatClntTmp2_OutFA.Value
              OUT_VeTRIR_U_BatBotlClnt_LoLvlVolt_Value: accessed-variable=VeTRIR_U_BatBotlClnt_LoLvlVolt.Value
              OUT_VeTRIR_b_BatBotlClntLoLvl_OC_Value: accessed-variable=VeTRIR_b_BatBotlClntLoLvl_OC.Value
              OUT_VeTRIR_T_HtrCorClnt_TmpIn_Value: accessed-variable=VeTRIR_T_HtrCorClnt_TmpIn.Value
              OUT_VeTRIR_b_HtrCorClnt_TmpIn_FA_Value: accessed-variable=VeTRIR_b_HtrCorClnt_TmpIn_FA.Value
              OUT_VeTRIR_T_HtrCorClnt_TmpOut_Value: accessed-variable=VeTRIR_T_HtrCorClnt_TmpOut.Value
              OUT_VeTRIR_b_HtrCorClnt_TmpOut_FA_Value: accessed-variable=VeTRIR_b_HtrCorClnt_TmpOut_FA.Value
              OUT_VeTRIR_b_AHP_EnblReq_Value: accessed-variable=VeTRIR_b_AHP_EnblReq.Value
              OUT_VeTRIR_Pct_AirHtrPwrTgt_Value: accessed-variable=VeTRIR_Pct_AirHtrPwrTgt.Value
              OUT_VeTRIR_b_AirHtrPwrTgt_FA_Value: accessed-variable=VeTRIR_b_AirHtrPwrTgt_FA.Value
              OUT_VeTRIR_T_HtmpRadCool_TmpIn_Value: accessed-variable=VeTRIR_T_HtmpRadCool_TmpIn.Value
              OUT_VeTRIR_b_HtmpRadCool_TmpIn_FA_Value: accessed-variable=VeTRIR_b_HtmpRadCool_TmpIn_FA.Value
              OUT_VeTRIR_T_HtmpRadCool_TmpOut_Value: accessed-variable=VeTRIR_T_HtmpRadCool_TmpOut.Value
              OUT_VeTRIR_b_HtmpRadCool_TmpOut_FA_Value: accessed-variable=VeTRIR_b_HtmpRadCool_TmpOut_FA.Value
              OUT_VeTRIR_T_HeatExCool_TmpOut_Value: accessed-variable=VeTRIR_T_HeatExCool_TmpOut.Value
              OUT_VeTRIR_b_HeatExCool_TmpOut_FA_Value: accessed-variable=VeTRIR_b_HeatExCool_TmpOut_FA.Value
              OUT_VeTRIR_P_SDS_HV_PwrAvgRaw_Value: accessed-variable=VeTRIR_P_SDS_HV_PwrAvgRaw.Value
              OUT_VeTRIR_b_SDS_HV_PwrAvgRaw_FA_Value: accessed-variable=VeTRIR_b_SDS_HV_PwrAvgRaw_FA.Value
              OUT_VeTRIR_b_SDS_HV_PwrAvgRcvd_Raw_Value: accessed-variable=VeTRIR_b_SDS_HV_PwrAvgRcvd_Raw.Value
              OUT_VeTRIR_T_SDS_ClntTmpIn_Act_Value: accessed-variable=VeTRIR_T_SDS_ClntTmpIn_Act.Value
              OUT_VeTRIR_b_SDS_ClntTmpIn_Act_FA_final_Value: accessed-variable=VeTRIR_b_SDS_ClntTmpIn_Act_FA_final.Value
              OUT_VeTRIR_b_SDS_ClntTmpIn_Act_Rcvd_Value: accessed-variable=VeTRIR_b_SDS_ClntTmpIn_Act_Rcvd.Value
              OUT_VeTRIR_e_SDS_ActualState_Value: accessed-variable=VeTRIR_e_SDS_ActualState.Value
              OUT_VeTRIR_b_SDS_ActualState_FA_Value: accessed-variable=VeTRIR_b_SDS_ActualState_FA.Value
              OUT_VeTRIR_b_SDS_ActualState_Rcvd_Value: accessed-variable=VeTRIR_b_SDS_ActualState_Rcvd.Value
              OUT_VeTRIR_e_SDS_MaxCoolingReq_Value: accessed-variable=VeTRIR_e_SDS_MaxCoolingReq.Value
              OUT_VeTRIR_b_SDS_MaxCoolingReq_FA_Value: accessed-variable=VeTRIR_b_SDS_MaxCoolingReq_FA.Value
              OUT_VeTRIR_b_SDS_MaxCoolingReq_Rcvd_Value: accessed-variable=VeTRIR_b_SDS_MaxCoolingReq_Rcvd.Value
              OUT_VeTRIR_T_SDS_ClntTmpIn_Tgt_Value: accessed-variable=VeTRIR_T_SDS_ClntTmpIn_Tgt.Value
              OUT_VeTRIR_b_SDS_ClntTmpIn_Tgt_FA_Value: accessed-variable=VeTRIR_b_SDS_ClntTmpIn_Tgt_FA.Value
              OUT_VeTRIR_b_SDS_ClntTmpIn_Tgt_Rcvd_Value: accessed-variable=VeTRIR_b_SDS_ClntTmpIn_Tgt_Rcvd.Value
              OUT_VeTRIR_Cnt_MC_RHSC2_Cooling_Value: accessed-variable=VeTRIR_Cnt_MC_RHSC2_Cooling.Value
              OUT_VeTRIR_e_HVACSt_Value: accessed-variable=VeTRIR_e_HVACSt.Value
              OUT_VeTRIR_b_SCCActv_Value: accessed-variable=VeTRIR_b_SCCActv.Value
              OUT_VeTRIR_e_HVACECOModeSts_Value: accessed-variable=VeTRIR_e_HVACECOModeSts.Value
              OUT_VeTRIR_b_HVACECOModeSts_FA_Value: accessed-variable=VeTRIR_b_HVACECOModeSts_FA.Value
              OUT_VeTRIR_e_ClimateInfo_Value: accessed-variable=VeTRIR_e_ClimateInfo.Value
              OUT_VeTRIR_b_ClimateInfo_FA_Value: accessed-variable=VeTRIR_b_ClimateInfo_FA.Value
              OUT_VeTRIR_b_KeepHotColdButtonStatus_Value: accessed-variable=VeTRIR_b_KeepHotColdButtonStatus.Value
              OUT_VeTRIR_b_KeepHotColdButtonStatus_FA_Value: accessed-variable=VeTRIR_b_KeepHotColdButtonStatus_FA.Value
              OUT_VeTRIR_b_Comfort_EnblAct_Value: accessed-variable=VeTRIR_b_Comfort_EnblAct.Value
              OUT_VeTRIR_b_Comfort_EnblAct_FA_Value: accessed-variable=VeTRIR_b_Comfort_EnblAct_FA.Value
              OUT_VeTRIR_b_TrunkStatus_Value: accessed-variable=VeTRIR_b_TrunkStatus.Value
              OUT_VeTRIR_b_TrunkStatus_FA_Value: accessed-variable=VeTRIR_b_TrunkStatus_FA.Value
              OUT_VeTRIR_b_LoadShed_Value: accessed-variable=VeTRIR_b_LoadShed.Value
              OUT_VeTRIR_b_LoadShed_FA_Value: accessed-variable=VeTRIR_b_LoadShed_FA.Value
              OUT_VeTRIR_e_HSW_Sts_Value: accessed-variable=VeTRIR_e_HSW_Sts.Value
              OUT_VeTRIR_b_HSW_Sts_FA_Value: accessed-variable=VeTRIR_b_HSW_Sts_FA.Value
              OUT_VeTRIR_b_HSW_Fail_Value: accessed-variable=VeTRIR_b_HSW_Fail.Value
              OUT_VeTRIR_e_FL_HS_Sts_Value: accessed-variable=VeTRIR_e_FL_HS_Sts.Value
              OUT_VeTRIR_b_FL_HS_Fail_Value: accessed-variable=VeTRIR_b_FL_HS_Fail.Value
              OUT_VeTRIR_e_FR_HS_Sts_Value: accessed-variable=VeTRIR_e_FR_HS_Sts.Value
              OUT_VeTRIR_b_FR_HS_Fail_Value: accessed-variable=VeTRIR_b_FR_HS_Fail.Value
              OUT_VeTRIR_e_RL_HS_Sts_Value: accessed-variable=VeTRIR_e_RL_HS_Sts.Value
              OUT_VeTRIR_b_RL_HS_Fail_Value: accessed-variable=VeTRIR_b_RL_HS_Fail.Value
              OUT_VeTRIR_e_RR_HS_Sts_Value: accessed-variable=VeTRIR_e_RR_HS_Sts.Value
              OUT_VeTRIR_b_RR_HS_Fail_Value: accessed-variable=VeTRIR_b_RR_HS_Fail.Value
              OUT_VeTRIR_e_FL_VS_Sts_Value: accessed-variable=VeTRIR_e_FL_VS_Sts.Value
              OUT_VeTRIR_b_FL_VS_Fail_Value: accessed-variable=VeTRIR_b_FL_VS_Fail.Value
              OUT_VeTRIR_e_FR_VS_Sts_Value: accessed-variable=VeTRIR_e_FR_VS_Sts.Value
              OUT_VeTRIR_b_FR_VS_Fail_Value: accessed-variable=VeTRIR_b_FR_VS_Fail.Value
              OUT_VeTRIR_e_RL_VS_Sts_Value: accessed-variable=VeTRIR_e_RL_VS_Sts.Value
              OUT_VeTRIR_b_RL_VS_Fail_Value: accessed-variable=VeTRIR_b_RL_VS_Fail.Value
              OUT_VeTRIR_e_RR_VS_Sts_Value: accessed-variable=VeTRIR_e_RR_VS_Sts.Value
              OUT_VeTRIR_b_RR_VS_Fail_Value: accessed-variable=VeTRIR_b_RR_VS_Fail.Value
          written-local-variables:
            73 x access:
              WV_VeTRIR_b_AHP_EnblReqFA_write_IRV: accessed-variable=VeTRIR_b_AHP_EnblReqFA_write_IRV
              WV_VeTRIR_b_AHP_EnblReq_write_IRV: accessed-variable=VeTRIR_b_AHP_EnblReq_write_IRV
              WV_VeTRIR_b_AirHtwPwrTgtFA_write_IRV: accessed-variable=VeTRIR_b_AirHtwPwrTgtFA_write_IRV
              WV_VeTRIR_Pct_AirHtwPwrTgt_write_IRV: accessed-variable=VeTRIR_Pct_AirHtwPwrTgt_write_IRV
              WV_VeTRIR_b_ClimateInfoFA_write_IRV: accessed-variable=VeTRIR_b_ClimateInfoFA_write_IRV
              WV_VeTRIR_e_ClimateInfo_write_IRV: accessed-variable=VeTRIR_e_ClimateInfo_write_IRV
              WV_VeTRIR_b_BCM_Comfort_EnblActFA_write_IRV: accessed-variable=VeTRIR_b_BCM_Comfort_EnblActFA_write_IRV
              WV_VeTRIR_b_BCM_Comfort_EnblAct_write_IRV: accessed-variable=VeTRIR_b_BCM_Comfort_EnblAct_write_IRV
              WV_VeTRIR_b_FL_HS_Fail_write_IRV: accessed-variable=VeTRIR_b_FL_HS_Fail_write_IRV
              WV_VeTRIR_e_FL_HS_Sts_write_IRV: accessed-variable=VeTRIR_e_FL_HS_Sts_write_IRV
              WV_VeTRIR_b_FL_VS_Fail_write_IRV: accessed-variable=VeTRIR_b_FL_VS_Fail_write_IRV
              WV_VeTRIR_e_FL_VS_Sts_write_IRV: accessed-variable=VeTRIR_e_FL_VS_Sts_write_IRV
              WV_VeTRIR_b_FR_HS_Fail_write_IRV: accessed-variable=VeTRIR_b_FR_HS_Fail_write_IRV
              WV_VeTRIR_e_FR_HS_Sts_write_IRV: accessed-variable=VeTRIR_e_FR_HS_Sts_write_IRV
              WV_VeTRIR_b_FR_VS_Fail_write_IRV: accessed-variable=VeTRIR_b_FR_VS_Fail_write_IRV
              WV_VeTRIR_e_FR_VS_Sts_write_IRV: accessed-variable=VeTRIR_e_FR_VS_Sts_write_IRV
              WV_VeTRIR_b_HSW_Fail_write_IRV: accessed-variable=VeTRIR_b_HSW_Fail_write_IRV
              WV_VeTRIR_b_HSW_StsFA_write_IRV: accessed-variable=VeTRIR_b_HSW_StsFA_write_IRV
              WV_VeTRIR_e_HSW_Sts_write_IRV: accessed-variable=VeTRIR_e_HSW_Sts_write_IRV
              WV_VeTRIR_b_HVACECOModeStsFA_write_IRV: accessed-variable=VeTRIR_b_HVACECOModeStsFA_write_IRV
              WV_VeTRIR_e_HVACECOModeSts_write_IRV: accessed-variable=VeTRIR_e_HVACECOModeSts_write_IRV
              WV_VeTRIR_e_HVACPrecCondSts_write_IRV: accessed-variable=VeTRIR_e_HVACPrecCondSts_write_IRV
              WV_VeTRIR_b_HV_BatClntTmp2_InFA_write_IRV: accessed-variable=VeTRIR_b_HV_BatClntTmp2_InFA_write_IRV
              WV_VeTRIR_T_HV_BatClntTmp2_In_write_IRV: accessed-variable=VeTRIR_T_HV_BatClntTmp2_In_write_IRV
              WV_HV_BatClntTmp2_In_AD_Prev_IRV: accessed-variable=HV_BatClntTmp2_In_AD_Prev_IRV
              WV_VeTRIR_b_HV_BatClntTmp2OutFA_write_IRV: accessed-variable=VeTRIR_b_HV_BatClntTmp2OutFA_write_IRV
              WV_VeTRIR_T_HV_BatClntTmp2_Out_write_IRV: accessed-variable=VeTRIR_T_HV_BatClntTmp2_Out_write_IRV
              WV_HV_BatClntTmpOut2_AD_Prev_IRV: accessed-variable=HV_BatClntTmpOut2_AD_Prev_IRV
              WV_VeTRIR_b_HV_BatClntTmp_InFA_write_IRV: accessed-variable=VeTRIR_b_HV_BatClntTmp_InFA_write_IRV
              WV_VeTRIR_T_HV_BatClntTmp_In_write_IRV: accessed-variable=VeTRIR_T_HV_BatClntTmp_In_write_IRV
              WV_HV_BatClntTmp_In_AD_Prev_IRV: accessed-variable=HV_BatClntTmp_In_AD_Prev_IRV
              WV_VeTRIR_b_HV_BatClntTmpOutFA_write_IRV: accessed-variable=VeTRIR_b_HV_BatClntTmpOutFA_write_IRV
              WV_VeTRIR_T_HV_BatClntTmp_Out_write_IRV: accessed-variable=VeTRIR_T_HV_BatClntTmp_Out_write_IRV
              WV_HV_BatClntTmpOut_AD_Prev_IRV: accessed-variable=HV_BatClntTmpOut_AD_Prev_IRV
              WV_VeTRIR_b_HeatExCool_TmpOutFA_write_IRV: accessed-variable=VeTRIR_b_HeatExCool_TmpOutFA_write_IRV
              WV_VeTRIR_T_HeatExCool_TmpOut_write_IRV: accessed-variable=VeTRIR_T_HeatExCool_TmpOut_write_IRV
              WV_VeTRIR_b_HtmpRadCool_TmpInFA_write_IRV: accessed-variable=VeTRIR_b_HtmpRadCool_TmpInFA_write_IRV
              WV_VeTRIR_T_HtmpRadCool_TmpIn_write_IRV: accessed-variable=VeTRIR_T_HtmpRadCool_TmpIn_write_IRV
              WV_VeTRIR_b_HtmpRadCool_TmpOutFA_write_IRV: accessed-variable=VeTRIR_b_HtmpRadCool_TmpOutFA_write_IRV
              WV_VeTRIR_T_HtmpRadCool_TmpOut_write_IRV: accessed-variable=VeTRIR_T_HtmpRadCool_TmpOut_write_IRV
              WV_VeTRIR_b_HtrCorClnt_TmpOutFA_write_IRV: accessed-variable=VeTRIR_b_HtrCorClnt_TmpOutFA_write_IRV
              WV_VeTRIR_T_HtrCorClnt_TmpOut_write_IRV: accessed-variable=VeTRIR_T_HtrCorClnt_TmpOut_write_IRV
              WV_VeTRIR_b_ETM_KeepHotColdButtonStatusFA_write_IRV: accessed-variable=VeTRIR_b_ETM_KeepHotColdButtonStatusFA_write_IRV
              WV_VeTRIR_b_ETM_KeepHotColdButtonStatus_write_IRV: accessed-variable=VeTRIR_b_ETM_KeepHotColdButtonStatus_write_IRV
              WV_VeTRIR_b_LoadShedFA_write_IRV: accessed-variable=VeTRIR_b_LoadShedFA_write_IRV
              WV_VeTRIR_b_LoadShed_write_IRV: accessed-variable=VeTRIR_b_LoadShed_write_IRV
              WV_VeTRIR_Cnt_MC_RHSC2_Cooling_write_IRV: accessed-variable=VeTRIR_Cnt_MC_RHSC2_Cooling_write_IRV
              WV_VeTRIR_b_RL_HS_Fail_write_IRV: accessed-variable=VeTRIR_b_RL_HS_Fail_write_IRV
              WV_VeTRIR_e_RL_HS_Sts_write_IRV: accessed-variable=VeTRIR_e_RL_HS_Sts_write_IRV
              WV_VeTRIR_b_RL_VS_Fail_write_IRV: accessed-variable=VeTRIR_b_RL_VS_Fail_write_IRV
              WV_VeTRIR_e_RL_VS_Sts_write_IRV: accessed-variable=VeTRIR_e_RL_VS_Sts_write_IRV
              WV_VeTRIR_b_RR_HS_Fail_write_IRV: accessed-variable=VeTRIR_b_RR_HS_Fail_write_IRV
              WV_VeTRIR_e_RR_HS_Sts_write_IRV: accessed-variable=VeTRIR_e_RR_HS_Sts_write_IRV
              WV_VeTRIR_b_RR_VS_Fail_write_IRV: accessed-variable=VeTRIR_b_RR_VS_Fail_write_IRV
              WV_VeTRIR_e_RR_VS_Sts_write_IRV: accessed-variable=VeTRIR_e_RR_VS_Sts_write_IRV
              WV_VeTRIR_b_SCCActv_write_IRV: accessed-variable=VeTRIR_b_SCCActv_write_IRV
              WV_VeTRIR_b_SDS_ActualStateFA_write_IRV: accessed-variable=VeTRIR_b_SDS_ActualStateFA_write_IRV
              WV_VeTRIR_e_SDS_ActualState_write_IRV: accessed-variable=VeTRIR_e_SDS_ActualState_write_IRV
              WV_VeTRIR_b_SDS_ActualStateSgnl_Rcvd_write_IRV: accessed-variable=VeTRIR_b_SDS_ActualStateSgnl_Rcvd_write_IRV
              WV_VeTRIR_b_SDS_ClntTmpIn_ActFA_write_IRV: accessed-variable=VeTRIR_b_SDS_ClntTmpIn_ActFA_write_IRV
              WV_VeTRIR_T_SDS_ClntTmpIn_Act_write_IRV: accessed-variable=VeTRIR_T_SDS_ClntTmpIn_Act_write_IRV
              WV_VeTRIR_b_SDS_ClntTmpIn_ActSgnl_Rcvd_write_IRV: accessed-variable=VeTRIR_b_SDS_ClntTmpIn_ActSgnl_Rcvd_write_IRV
              WV_VeTRIR_b_SDS_ClntTmpIn_TgtFA_write_IRV: accessed-variable=VeTRIR_b_SDS_ClntTmpIn_TgtFA_write_IRV
              WV_VeTRIR_T_SDS_ClntTmpIn_Tgt_write_IRV: accessed-variable=VeTRIR_T_SDS_ClntTmpIn_Tgt_write_IRV
              WV_VeTRIR_b_SDS_ClntTmpIn_TgtSgnl_Rcvd_write_IRV: accessed-variable=VeTRIR_b_SDS_ClntTmpIn_TgtSgnl_Rcvd_write_IRV
              WV_VeTRIR_b_SDS_HV_PwrAvgFA_write_IRV: accessed-variable=VeTRIR_b_SDS_HV_PwrAvgFA_write_IRV
              WV_VeTRIR_P_SDS_HV_PwrAvg_write_IRV: accessed-variable=VeTRIR_P_SDS_HV_PwrAvg_write_IRV
              WV_VeTRIR_b_SDS_HV_PwrAvgSgnl_Rcvd_write_IRV: accessed-variable=VeTRIR_b_SDS_HV_PwrAvgSgnl_Rcvd_write_IRV
              WV_VeTRIR_b_SDS_MaxCoolingReqFA_write_IRV: accessed-variable=VeTRIR_b_SDS_MaxCoolingReqFA_write_IRV
              WV_VeTRIR_e_SDS_MaxCoolingReq_write_IRV: accessed-variable=VeTRIR_e_SDS_MaxCoolingReq_write_IRV
              WV_VeTRIR_b_SDS_MaxCoolingReqSgnl_Rcvd_write_IRV: accessed-variable=VeTRIR_b_SDS_MaxCoolingReqSgnl_Rcvd_write_IRV
              WV_VeTRIR_b_TrunkStatusFA_write_IRV: accessed-variable=VeTRIR_b_TrunkStatusFA_write_IRV
              WV_VeTRIR_b_TrunkStatus_write_IRV: accessed-variable=VeTRIR_b_TrunkStatus_write_IRV
        TRIR_MedTEH
          data-receive-point-by-arguments:
            4 x access:
              IN_VeTRIB_T_HtrCorClnt_TmpIn_Value: accessed-variable=VeTRIB_T_HtrCorClnt_TmpIn.Value
              IN_VeTRIB_U_BatBotlClnt_LoLvlVolt_Value: accessed-variable=VeTRIB_U_BatBotlClnt_LoLvlVolt.Value
              IN_VeTRIB_b_BatBotlClntLoLvl_FA_Value: accessed-variable=VeTRIB_b_BatBotlClntLoLvl_FA.Value
              IN_VeTRIB_b_HtrCorClnt_TmpIn_FA_Value: accessed-variable=VeTRIB_b_HtrCorClnt_TmpIn_FA.Value
          data-send-points:
            72 x access:
              OUT_VeTRIR_T_HV_BatClntTmp_In_Value: accessed-variable=VeTRIR_T_HV_BatClntTmp_In.Value
              OUT_VeTRIR_b_HV_BatClntTmp_In_FA_Value: accessed-variable=VeTRIR_b_HV_BatClntTmp_In_FA.Value
              OUT_VeTRIR_T_HV_BatClntTmpOut_Value: accessed-variable=VeTRIR_T_HV_BatClntTmpOut.Value
              OUT_VeTRIR_b_HV_BatClntTmp_Out_FA_Value: accessed-variable=VeTRIR_b_HV_BatClntTmp_Out_FA.Value
              OUT_VeTRIR_T_HV_BatClntTmp2_In_Value: accessed-variable=VeTRIR_T_HV_BatClntTmp2_In.Value
              OUT_VeTRIR_b_HV_BatClntTmp2_InFA_Value: accessed-variable=VeTRIR_b_HV_BatClntTmp2_InFA.Value
              OUT_VeTRIR_T_HV_BatClntTmpOut2_Value: accessed-variable=VeTRIR_T_HV_BatClntTmpOut2.Value
              OUT_VeTRIR_b_HV_BatClntTmp2_OutFA_Value: accessed-variable=VeTRIR_b_HV_BatClntTmp2_OutFA.Value
              OUT_VeTRIR_U_BatBotlClnt_LoLvlVolt_Value: accessed-variable=VeTRIR_U_BatBotlClnt_LoLvlVolt.Value
              OUT_VeTRIR_b_BatBotlClntLoLvl_OC_Value: accessed-variable=VeTRIR_b_BatBotlClntLoLvl_OC.Value
              OUT_VeTRIR_T_HtrCorClnt_TmpIn_Value: accessed-variable=VeTRIR_T_HtrCorClnt_TmpIn.Value
              OUT_VeTRIR_b_HtrCorClnt_TmpIn_FA_Value: accessed-variable=VeTRIR_b_HtrCorClnt_TmpIn_FA.Value
              OUT_VeTRIR_Pct_AirHtrPwrTgt_Value: accessed-variable=VeTRIR_Pct_AirHtrPwrTgt.Value
              OUT_VeTRIR_b_AirHtrPwrTgt_FA_Value: accessed-variable=VeTRIR_b_AirHtrPwrTgt_FA.Value
              OUT_VeTRIR_b_AHP_EnblReq_Value: accessed-variable=VeTRIR_b_AHP_EnblReq.Value
              OUT_VeTRIR_T_HtrCorClnt_TmpOut_Value: accessed-variable=VeTRIR_T_HtrCorClnt_TmpOut.Value
              OUT_VeTRIR_b_HtrCorClnt_TmpOut_FA_Value: accessed-variable=VeTRIR_b_HtrCorClnt_TmpOut_FA.Value
              OUT_VeTRIR_T_HtmpRadCool_TmpIn_Value: accessed-variable=VeTRIR_T_HtmpRadCool_TmpIn.Value
              OUT_VeTRIR_b_HtmpRadCool_TmpIn_FA_Value: accessed-variable=VeTRIR_b_HtmpRadCool_TmpIn_FA.Value
              OUT_VeTRIR_T_HtmpRadCool_TmpOut_Value: accessed-variable=VeTRIR_T_HtmpRadCool_TmpOut.Value
              OUT_VeTRIR_b_HtmpRadCool_TmpOut_FA_Value: accessed-variable=VeTRIR_b_HtmpRadCool_TmpOut_FA.Value
              OUT_VeTRIR_T_HeatExCool_TmpOut_Value: accessed-variable=VeTRIR_T_HeatExCool_TmpOut.Value
              OUT_VeTRIR_b_HeatExCool_TmpOut_FA_Value: accessed-variable=VeTRIR_b_HeatExCool_TmpOut_FA.Value
              OUT_VeTRIR_e_HSW_Sts_Value: accessed-variable=VeTRIR_e_HSW_Sts.Value
              OUT_VeTRIR_b_HSW_Sts_FA_Value: accessed-variable=VeTRIR_b_HSW_Sts_FA.Value
              OUT_VeTRIR_b_HSW_Fail_Value: accessed-variable=VeTRIR_b_HSW_Fail.Value
              OUT_VeTRIR_e_FL_HS_Sts_Value: accessed-variable=VeTRIR_e_FL_HS_Sts.Value
              OUT_VeTRIR_b_FL_HS_Fail_Value: accessed-variable=VeTRIR_b_FL_HS_Fail.Value
              OUT_VeTRIR_e_FR_HS_Sts_Value: accessed-variable=VeTRIR_e_FR_HS_Sts.Value
              OUT_VeTRIR_b_FR_HS_Fail_Value: accessed-variable=VeTRIR_b_FR_HS_Fail.Value
              OUT_VeTRIR_e_RL_HS_Sts_Value: accessed-variable=VeTRIR_e_RL_HS_Sts.Value
              OUT_VeTRIR_b_RL_HS_Fail_Value: accessed-variable=VeTRIR_b_RL_HS_Fail.Value
              OUT_VeTRIR_e_RR_HS_Sts_Value: accessed-variable=VeTRIR_e_RR_HS_Sts.Value
              OUT_VeTRIR_b_RR_HS_Fail_Value: accessed-variable=VeTRIR_b_RR_HS_Fail.Value
              OUT_VeTRIR_e_FL_VS_Sts_Value: accessed-variable=VeTRIR_e_FL_VS_Sts.Value
              OUT_VeTRIR_b_FL_VS_Fail_Value: accessed-variable=VeTRIR_b_FL_VS_Fail.Value
              OUT_VeTRIR_e_FR_VS_Sts_Value: accessed-variable=VeTRIR_e_FR_VS_Sts.Value
              OUT_VeTRIR_b_FR_VS_Fail_Value: accessed-variable=VeTRIR_b_FR_VS_Fail.Value
              OUT_VeTRIR_e_RL_VS_Sts_Value: accessed-variable=VeTRIR_e_RL_VS_Sts.Value
              OUT_VeTRIR_b_RL_VS_Fail_Value: accessed-variable=VeTRIR_b_RL_VS_Fail.Value
              OUT_VeTRIR_e_RR_VS_Sts_Value: accessed-variable=VeTRIR_e_RR_VS_Sts.Value
              OUT_VeTRIR_b_RR_VS_Fail_Value: accessed-variable=VeTRIR_b_RR_VS_Fail.Value
              OUT_VeTRIR_P_SDS_HV_PwrAvgRaw_Value: accessed-variable=VeTRIR_P_SDS_HV_PwrAvgRaw.Value
              OUT_VeTRIR_b_SDS_HV_PwrAvgRaw_FA_Value: accessed-variable=VeTRIR_b_SDS_HV_PwrAvgRaw_FA.Value
              OUT_VeTRIR_b_SDS_HV_PwrAvgRcvd_Raw_Value: accessed-variable=VeTRIR_b_SDS_HV_PwrAvgRcvd_Raw.Value
              OUT_VeTRIR_T_SDS_ClntTmpIn_Act_Value: accessed-variable=VeTRIR_T_SDS_ClntTmpIn_Act.Value
              OUT_VeTRIR_b_SDS_ClntTmpIn_Act_FA_final_Value: accessed-variable=VeTRIR_b_SDS_ClntTmpIn_Act_FA_final.Value
              OUT_VeTRIR_b_SDS_ClntTmpIn_Act_Rcvd_Value: accessed-variable=VeTRIR_b_SDS_ClntTmpIn_Act_Rcvd.Value
              OUT_VeTRIR_T_SDS_ClntTmpIn_Tgt_Value: accessed-variable=VeTRIR_T_SDS_ClntTmpIn_Tgt.Value
              OUT_VeTRIR_b_SDS_ClntTmpIn_Tgt_FA_Value: accessed-variable=VeTRIR_b_SDS_ClntTmpIn_Tgt_FA.Value
              OUT_VeTRIR_b_SDS_ClntTmpIn_Tgt_Rcvd_Value: accessed-variable=VeTRIR_b_SDS_ClntTmpIn_Tgt_Rcvd.Value
              OUT_VeTRIR_e_SDS_ActualState_Value: accessed-variable=VeTRIR_e_SDS_ActualState.Value
              OUT_VeTRIR_b_SDS_ActualState_FA_Value: accessed-variable=VeTRIR_b_SDS_ActualState_FA.Value
              OUT_VeTRIR_b_SDS_ActualState_Rcvd_Value: accessed-variable=VeTRIR_b_SDS_ActualState_Rcvd.Value
              OUT_VeTRIR_e_SDS_MaxCoolingReq_Value: accessed-variable=VeTRIR_e_SDS_MaxCoolingReq.Value
              OUT_VeTRIR_b_SDS_MaxCoolingReq_FA_Value: accessed-variable=VeTRIR_b_SDS_MaxCoolingReq_FA.Value
              OUT_VeTRIR_b_SDS_MaxCoolingReq_Rcvd_Value: accessed-variable=VeTRIR_b_SDS_MaxCoolingReq_Rcvd.Value
              OUT_VeTRIR_Cnt_MC_RHSC2_Cooling_Value: accessed-variable=VeTRIR_Cnt_MC_RHSC2_Cooling.Value
              OUT_VeTRIR_b_SCCActv_Value: accessed-variable=VeTRIR_b_SCCActv.Value
              OUT_VeTRIR_e_HVACSt_Value: accessed-variable=VeTRIR_e_HVACSt.Value
              OUT_VeTRIR_e_HVACECOModeSts_Value: accessed-variable=VeTRIR_e_HVACECOModeSts.Value
              OUT_VeTRIR_b_HVACECOModeSts_FA_Value: accessed-variable=VeTRIR_b_HVACECOModeSts_FA.Value
              OUT_VeTRIR_e_ClimateInfo_Value: accessed-variable=VeTRIR_e_ClimateInfo.Value
              OUT_VeTRIR_b_ClimateInfo_FA_Value: accessed-variable=VeTRIR_b_ClimateInfo_FA.Value
              OUT_VeTRIR_b_KeepHotColdButtonStatus_Value: accessed-variable=VeTRIR_b_KeepHotColdButtonStatus.Value
              OUT_VeTRIR_b_KeepHotColdButtonStatus_FA_Value: accessed-variable=VeTRIR_b_KeepHotColdButtonStatus_FA.Value
              OUT_VeTRIR_b_Comfort_EnblAct_Value: accessed-variable=VeTRIR_b_Comfort_EnblAct.Value
              OUT_VeTRIR_b_Comfort_EnblAct_FA_Value: accessed-variable=VeTRIR_b_Comfort_EnblAct_FA.Value
              OUT_VeTRIR_b_TrunkStatus_Value: accessed-variable=VeTRIR_b_TrunkStatus.Value
              OUT_VeTRIR_b_TrunkStatus_FA_Value: accessed-variable=VeTRIR_b_TrunkStatus_FA.Value
              OUT_VeTRIR_b_LoadShed_Value: accessed-variable=VeTRIR_b_LoadShed.Value
              OUT_VeTRIR_b_LoadShed_FA_Value: accessed-variable=VeTRIR_b_LoadShed_FA.Value
          read-local-variables:
            73 x access:
              RV_HV_BatClntTmp2_In_AD_Prev_IRV: accessed-variable=HV_BatClntTmp2_In_AD_Prev_IRV
              RV_HV_BatClntTmpOut2_AD_Prev_IRV: accessed-variable=HV_BatClntTmpOut2_AD_Prev_IRV
              RV_HV_BatClntTmpOut_AD_Prev_IRV: accessed-variable=HV_BatClntTmpOut_AD_Prev_IRV
              RV_HV_BatClntTmp_In_AD_Prev_IRV: accessed-variable=HV_BatClntTmp_In_AD_Prev_IRV
              RV_VeTRIR_Cnt_MC_RHSC2_Cooling_write_IRV: accessed-variable=VeTRIR_Cnt_MC_RHSC2_Cooling_write_IRV
              RV_VeTRIR_P_SDS_HV_PwrAvg_write_IRV: accessed-variable=VeTRIR_P_SDS_HV_PwrAvg_write_IRV
              RV_VeTRIR_Pct_AirHtwPwrTgt_write_IRV: accessed-variable=VeTRIR_Pct_AirHtwPwrTgt_write_IRV
              RV_VeTRIR_T_HV_BatClntTmp2_In_write_IRV: accessed-variable=VeTRIR_T_HV_BatClntTmp2_In_write_IRV
              RV_VeTRIR_T_HV_BatClntTmp2_Out_write_IRV: accessed-variable=VeTRIR_T_HV_BatClntTmp2_Out_write_IRV
              RV_VeTRIR_T_HV_BatClntTmp_In_write_IRV: accessed-variable=VeTRIR_T_HV_BatClntTmp_In_write_IRV, variation-point={short-label=vpRV_VeTRIR_T_HV_BatClntTmp_In_write_IRV, sw-syscond=1}
              RV_VeTRIR_T_HV_BatClntTmp_Out_write_IRV: accessed-variable=VeTRIR_T_HV_BatClntTmp_Out_write_IRV, variation-point={short-label=vpRV_VeTRIR_T_HV_BatClntTmp_Out_write_IRV, sw-syscond=1}
              RV_VeTRIR_T_HeatExCool_TmpOut_write_IRV: accessed-variable=VeTRIR_T_HeatExCool_TmpOut_write_IRV
              RV_VeTRIR_T_HtmpRadCool_TmpIn_write_IRV: accessed-variable=VeTRIR_T_HtmpRadCool_TmpIn_write_IRV
              RV_VeTRIR_T_HtmpRadCool_TmpOut_write_IRV: accessed-variable=VeTRIR_T_HtmpRadCool_TmpOut_write_IRV
              RV_VeTRIR_T_HtrCorClnt_TmpOut_write_IRV: accessed-variable=VeTRIR_T_HtrCorClnt_TmpOut_write_IRV
              RV_VeTRIR_T_SDS_ClntTmpIn_Act_write_IRV: accessed-variable=VeTRIR_T_SDS_ClntTmpIn_Act_write_IRV
              RV_VeTRIR_T_SDS_ClntTmpIn_Tgt_write_IRV: accessed-variable=VeTRIR_T_SDS_ClntTmpIn_Tgt_write_IRV
              RV_VeTRIR_b_AHP_EnblReqFA_write_IRV: accessed-variable=VeTRIR_b_AHP_EnblReqFA_write_IRV
              RV_VeTRIR_b_AHP_EnblReq_write_IRV: accessed-variable=VeTRIR_b_AHP_EnblReq_write_IRV
              RV_VeTRIR_b_AirHtwPwrTgtFA_write_IRV: accessed-variable=VeTRIR_b_AirHtwPwrTgtFA_write_IRV
              RV_VeTRIR_b_BCM_Comfort_EnblActFA_write_IRV: accessed-variable=VeTRIR_b_BCM_Comfort_EnblActFA_write_IRV
              RV_VeTRIR_b_BCM_Comfort_EnblAct_write_IRV: accessed-variable=VeTRIR_b_BCM_Comfort_EnblAct_write_IRV
              RV_VeTRIR_b_ClimateInfoFA_write_IRV: accessed-variable=VeTRIR_b_ClimateInfoFA_write_IRV
              RV_VeTRIR_b_ETM_KeepHotColdButtonStatusFA_write_IRV: accessed-variable=VeTRIR_b_ETM_KeepHotColdButtonStatusFA_write_IRV
              RV_VeTRIR_b_ETM_KeepHotColdButtonStatus_write_IRV: accessed-variable=VeTRIR_b_ETM_KeepHotColdButtonStatus_write_IRV
              RV_VeTRIR_b_FL_HS_Fail_write_IRV: accessed-variable=VeTRIR_b_FL_HS_Fail_write_IRV
              RV_VeTRIR_b_FL_VS_Fail_write_IRV: accessed-variable=VeTRIR_b_FL_VS_Fail_write_IRV
              RV_VeTRIR_b_FR_HS_Fail_write_IRV: accessed-variable=VeTRIR_b_FR_HS_Fail_write_IRV
              RV_VeTRIR_b_FR_VS_Fail_write_IRV: accessed-variable=VeTRIR_b_FR_VS_Fail_write_IRV
              RV_VeTRIR_b_HSW_Fail_write_IRV: accessed-variable=VeTRIR_b_HSW_Fail_write_IRV
              RV_VeTRIR_b_HSW_StsFA_write_IRV: accessed-variable=VeTRIR_b_HSW_StsFA_write_IRV
              RV_VeTRIR_b_HVACECOModeStsFA_write_IRV: accessed-variable=VeTRIR_b_HVACECOModeStsFA_write_IRV
              RV_VeTRIR_b_HV_BatClntTmp2OutFA_write_IRV: accessed-variable=VeTRIR_b_HV_BatClntTmp2OutFA_write_IRV
              RV_VeTRIR_b_HV_BatClntTmp2_InFA_write_IRV: accessed-variable=VeTRIR_b_HV_BatClntTmp2_InFA_write_IRV
              RV_VeTRIR_b_HV_BatClntTmpOutFA_write_IRV: accessed-variable=VeTRIR_b_HV_BatClntTmpOutFA_write_IRV, variation-point={short-label=vpRV_VeTRIR_b_HV_BatClntTmpOutFA_write_IRV, sw-syscond=1}
              RV_VeTRIR_b_HV_BatClntTmp_InFA_write_IRV: accessed-variable=VeTRIR_b_HV_BatClntTmp_InFA_write_IRV, variation-point={short-label=vpRV_VeTRIR_b_HV_BatClntTmp_InFA_write_IRV, sw-syscond=1}
              RV_VeTRIR_b_HeatExCool_TmpOutFA_write_IRV: accessed-variable=VeTRIR_b_HeatExCool_TmpOutFA_write_IRV
              RV_VeTRIR_b_HtmpRadCool_TmpInFA_write_IRV: accessed-variable=VeTRIR_b_HtmpRadCool_TmpInFA_write_IRV
              RV_VeTRIR_b_HtmpRadCool_TmpOutFA_write_IRV: accessed-variable=VeTRIR_b_HtmpRadCool_TmpOutFA_write_IRV
              RV_VeTRIR_b_HtrCorClnt_TmpOutFA_write_IRV: accessed-variable=VeTRIR_b_HtrCorClnt_TmpOutFA_write_IRV
              RV_VeTRIR_b_LoadShedFA_write_IRV: accessed-variable=VeTRIR_b_LoadShedFA_write_IRV
              RV_VeTRIR_b_LoadShed_write_IRV: accessed-variable=VeTRIR_b_LoadShed_write_IRV
              RV_VeTRIR_b_RL_HS_Fail_write_IRV: accessed-variable=VeTRIR_b_RL_HS_Fail_write_IRV
              RV_VeTRIR_b_RL_VS_Fail_write_IRV: accessed-variable=VeTRIR_b_RL_VS_Fail_write_IRV
              RV_VeTRIR_b_RR_HS_Fail_write_IRV: accessed-variable=VeTRIR_b_RR_HS_Fail_write_IRV
              RV_VeTRIR_b_RR_VS_Fail_write_IRV: accessed-variable=VeTRIR_b_RR_VS_Fail_write_IRV
              RV_VeTRIR_b_SCCActv_write_IRV: accessed-variable=VeTRIR_b_SCCActv_write_IRV
              RV_VeTRIR_b_SDS_ActualStateFA_write_IRV: accessed-variable=VeTRIR_b_SDS_ActualStateFA_write_IRV
              RV_VeTRIR_b_SDS_ActualStateSgnl_Rcvd_write_IRV: accessed-variable=VeTRIR_b_SDS_ActualStateSgnl_Rcvd_write_IRV
              RV_VeTRIR_b_SDS_ClntTmpIn_ActFA_write_IRV: accessed-variable=VeTRIR_b_SDS_ClntTmpIn_ActFA_write_IRV
              RV_VeTRIR_b_SDS_ClntTmpIn_ActSgnl_Rcvd_write_IRV: accessed-variable=VeTRIR_b_SDS_ClntTmpIn_ActSgnl_Rcvd_write_IRV
              RV_VeTRIR_b_SDS_ClntTmpIn_TgtFA_write_IRV: accessed-variable=VeTRIR_b_SDS_ClntTmpIn_TgtFA_write_IRV
              RV_VeTRIR_b_SDS_ClntTmpIn_TgtSgnl_Rcvd_write_IRV: accessed-variable=VeTRIR_b_SDS_ClntTmpIn_TgtSgnl_Rcvd_write_IRV
              RV_VeTRIR_b_SDS_HV_PwrAvgFA_write_IRV: accessed-variable=VeTRIR_b_SDS_HV_PwrAvgFA_write_IRV
              RV_VeTRIR_b_SDS_HV_PwrAvgSgnl_Rcvd_write_IRV: accessed-variable=VeTRIR_b_SDS_HV_PwrAvgSgnl_Rcvd_write_IRV
              RV_VeTRIR_b_SDS_MaxCoolingReqFA_write_IRV: accessed-variable=VeTRIR_b_SDS_MaxCoolingReqFA_write_IRV
              RV_VeTRIR_b_SDS_MaxCoolingReqSgnl_Rcvd_write_IRV: accessed-variable=VeTRIR_b_SDS_MaxCoolingReqSgnl_Rcvd_write_IRV
              RV_VeTRIR_b_TrunkStatusFA_write_IRV: accessed-variable=VeTRIR_b_TrunkStatusFA_write_IRV
              RV_VeTRIR_b_TrunkStatus_write_IRV: accessed-variable=VeTRIR_b_TrunkStatus_write_IRV
              RV_VeTRIR_e_ClimateInfo_write_IRV: accessed-variable=VeTRIR_e_ClimateInfo_write_IRV
              RV_VeTRIR_e_FL_HS_Sts_write_IRV: accessed-variable=VeTRIR_e_FL_HS_Sts_write_IRV
              RV_VeTRIR_e_FL_VS_Sts_write_IRV: accessed-variable=VeTRIR_e_FL_VS_Sts_write_IRV
              RV_VeTRIR_e_FR_HS_Sts_write_IRV: accessed-variable=VeTRIR_e_FR_HS_Sts_write_IRV
              RV_VeTRIR_e_FR_VS_Sts_write_IRV: accessed-variable=VeTRIR_e_FR_VS_Sts_write_IRV
              RV_VeTRIR_e_HSW_Sts_write_IRV: accessed-variable=VeTRIR_e_HSW_Sts_write_IRV
              RV_VeTRIR_e_HVACECOModeSts_write_IRV: accessed-variable=VeTRIR_e_HVACECOModeSts_write_IRV
              RV_VeTRIR_e_HVACPrecCondSts_write_IRV: accessed-variable=VeTRIR_e_HVACPrecCondSts_write_IRV
              RV_VeTRIR_e_RL_HS_Sts_write_IRV: accessed-variable=VeTRIR_e_RL_HS_Sts_write_IRV
              RV_VeTRIR_e_RL_VS_Sts_write_IRV: accessed-variable=VeTRIR_e_RL_VS_Sts_write_IRV
              RV_VeTRIR_e_RR_HS_Sts_write_IRV: accessed-variable=VeTRIR_e_RR_HS_Sts_write_IRV
              RV_VeTRIR_e_RR_VS_Sts_write_IRV: accessed-variable=VeTRIR_e_RR_VS_Sts_write_IRV
              RV_VeTRIR_e_SDS_ActualState_write_IRV: accessed-variable=VeTRIR_e_SDS_ActualState_write_IRV
              RV_VeTRIR_e_SDS_MaxCoolingReq_write_IRV: accessed-variable=VeTRIR_e_SDS_MaxCoolingReq_write_IRV
          written-local-variables:
            4 x access:
              WV_HV_BatClntTmp2_In_AD_Prev_IRV: accessed-variable=HV_BatClntTmp2_In_AD_Prev_IRV
              WV_HV_BatClntTmpOut2_AD_Prev_IRV: accessed-variable=HV_BatClntTmpOut2_AD_Prev_IRV
              WV_HV_BatClntTmpOut_AD_Prev_IRV: accessed-variable=HV_BatClntTmpOut_AD_Prev_IRV
              WV_HV_BatClntTmp_In_AD_Prev_IRV: accessed-variable=HV_BatClntTmp_In_AD_Prev_IRV
        FsftTRIR_Pct_AirHtwPwrTgt  # Electric Air Heater (EAH) power target (from BCM) Failsoft function
          written-local-variables:
            access WV_VeTRIR_b_AirHtwPwrTgtFA_write_IRV: accessed-variable=VeTRIR_b_AirHtwPwrTgtFA_write_IRV
        FsftTRIR_T_HV_BatClntTmp2Out  # Battery Temperature Outlet Sensor 2 (BTOS2) Failsoft function
          written-local-variables:
            access WV_VeTRIR_b_HV_BatClntTmp2OutFA_write_IRV: accessed-variable=VeTRIR_b_HV_BatClntTmp2OutFA_write_IRV
        FsftTRIR_T_HV_BatClntTmp2_In  # Battery Temperature Inlet Sensor 2 (BTIS2) Failsoft function
          written-local-variables:
            access WV_VeTRIR_b_HV_BatClntTmp2_InFA_write_IRV: accessed-variable=VeTRIR_b_HV_BatClntTmp2_InFA_write_IRV
        FsftTRIR_T_HV_BatClntTmpOut: variation-point={short-label=vpFsftTRIR_T_HV_BatClntTmpOut, sw-syscond=1}  # Battery Temperature Outlet Sensor (BTOS) Failsoft function
          written-local-variables:
            access WV_VeTRIR_b_HV_BatClntTmpOutFA_write_IRV: accessed-variable=VeTRIR_b_HV_BatClntTmpOutFA_write_IRV, variation-point={short-label=vpWV_VeTRIR_b_HV_BatClntTmpOutFA_write_IRV, sw-syscond=1}
        FsftTRIR_T_HV_BatClntTmp_In: variation-point={short-label=vpFsftTRIR_T_HV_BatClntTmp_In, sw-syscond=1}  # Battery Temperature Inlet Sensor (BTIS) Failsoft function
          written-local-variables:
            access WV_VeTRIR_b_HV_BatClntTmp_InFA_write_IRV: accessed-variable=VeTRIR_b_HV_BatClntTmp_InFA_write_IRV, variation-point={short-label=vpWV_VeTRIR_b_HV_BatClntTmp_InFA_write_IRV, sw-syscond=1}
        FsftTRIR_T_SDS_ClntTmpIn_Act
          written-local-variables:
            access WV_VeTRIR_b_SDS_ClntTmpIn_ActFA_write_IRV: accessed-variable=VeTRIR_b_SDS_ClntTmpIn_ActFA_write_IRV
            access WV_VeTRIR_b_SDS_ClntTmpIn_ActSgnl_Rcvd_write_IRV: accessed-variable=VeTRIR_b_SDS_ClntTmpIn_ActSgnl_Rcvd_write_IRV
        FsftTRIR_b_AHP_EnblReq  # Auxiliary Heater Pump (AHP) enable request Failsoft function
          written-local-variables:
            access WV_VeTRIR_b_AHP_EnblReqFA_write_IRV: accessed-variable=VeTRIR_b_AHP_EnblReqFA_write_IRV
        FsftTRIR_b_BCM_Comfort_EnblAct  # Accessory delay activation Failsoft function
          written-local-variables:
            access WV_VeTRIR_b_BCM_Comfort_EnblActFA_write_IRV: accessed-variable=VeTRIR_b_BCM_Comfort_EnblActFA_write_IRV
        FsftTRIR_b_ClimateInfo  # HVAC conditions affecting the Start/Stop functionality Failsoft function
          written-local-variables:
            access WV_VeTRIR_b_ClimateInfoFA_write_IRV: accessed-variable=VeTRIR_b_ClimateInfoFA_write_IRV
        FsftTRIR_b_ETM_KeepHotColdButtonStatus  # Keep car hot/cold request - button status Failsoft function
          written-local-variables:
            access WV_VeTRIR_b_ETM_KeepHotColdButtonStatusFA_write_IRV: accessed-variable=VeTRIR_b_ETM_KeepHotColdButtonStatusFA_write_IRV
        FsftTRIR_b_HSW_Sts: variation-point={short-label=vpFsftTRIR_b_HSW_Sts, sw-syscond=1}  # Heated Steering Wheel status Failsoft function
          written-local-variables:
            access WV_VeTRIR_b_HSW_StsFA_write_IRV: accessed-variable=VeTRIR_b_HSW_StsFA_write_IRV, variation-point={short-label=vpWV_VeTRIR_b_HSW_StsFA_write_IRV, sw-syscond=1}
        FsftTRIR_b_HVACECOModeSts  # Heating Ventilation Air Conditioning (HVAC) ECO mode status Failsoft function
          written-local-variables:
            access WV_VeTRIR_b_HVACECOModeStsFA_write_IRV: accessed-variable=VeTRIR_b_HVACECOModeStsFA_write_IRV
        FsftTRIR_b_HVACPrecCondSts  # HVAC - cabin preconditioning status Failsoft function
        FsftTRIR_b_HeatExCool_TmpOut  # Heat Exchanger Coolant Temperature Outlet Sensor (HXCTOS) Failsoft function
          written-local-variables:
            access WV_VeTRIR_b_HeatExCool_TmpOutFA_write_IRV: accessed-variable=VeTRIR_b_HeatExCool_TmpOutFA_write_IRV
        FsftTRIR_b_HtmpRadCool_TmpIn  # High temperature Radiator Coolant Temperature Inlet Sensor (HRCTIS) Failsoft function
          written-local-variables:
            access WV_VeTRIR_b_HtmpRadCool_TmpInFA_write_IRV: accessed-variable=VeTRIR_b_HtmpRadCool_TmpInFA_write_IRV
        FsftTRIR_b_HtmpRadCool_TmpOut  # High temperature Radiator Coolant Temperature Outlet Sensor (HRCTOS) Failsoft function
          written-local-variables:
            access WV_VeTRIR_b_HtmpRadCool_TmpOutFA_write_IRV: accessed-variable=VeTRIR_b_HtmpRadCool_TmpOutFA_write_IRV
        FsftTRIR_b_HtrCorClnt_TmpOut  # Heater Core Coolant Temperature Outlet Sensor (HCCTOS) Failsoft function
          written-local-variables:
            access WV_VeTRIR_b_HtrCorClnt_TmpOutFA_write_IRV: accessed-variable=VeTRIR_b_HtrCorClnt_TmpOutFA_write_IRV
        FsftTRIR_b_LoadShed  # 14V Powernet load shedding status Failsoft function
          written-local-variables:
            access WV_VeTRIR_b_LoadShedFA_write_IRV: accessed-variable=VeTRIR_b_LoadShedFA_write_IRV
        FsftTRIR_b_SCCActv  # Scheduled Cabin Conditioning (SCC) remote-start Failsoft function
        FsftTRIR_b_TrunkStatus  # Rear hatch status Failsoft function
          written-local-variables:
            access WV_VeTRIR_b_TrunkStatusFA_write_IRV: accessed-variable=VeTRIR_b_TrunkStatusFA_write_IRV
        PokeTRIR_Cnt_MC_RHSC2_Cooling
          written-local-variables:
            access WV_VeTRIR_Cnt_MC_RHSC2_Cooling_write_IRV: accessed-variable=VeTRIR_Cnt_MC_RHSC2_Cooling_write_IRV
        PokeTRIR_P_SDS_HV_PwrAvg
          written-local-variables:
            access WV_VeTRIR_P_SDS_HV_PwrAvg_write_IRV: accessed-variable=VeTRIR_P_SDS_HV_PwrAvg_write_IRV
            access WV_VeTRIR_b_SDS_HV_PwrAvgFA_write_IRV: accessed-variable=VeTRIR_b_SDS_HV_PwrAvgFA_write_IRV
            access WV_VeTRIR_b_SDS_HV_PwrAvgSgnl_Rcvd_write_IRV: accessed-variable=VeTRIR_b_SDS_HV_PwrAvgSgnl_Rcvd_write_IRV
        PokeTRIR_Pct_AirHtwPwrTgt  # Electric Air Heater (EAH) power target (from BCM) Poke function
          written-local-variables:
            access WV_VeTRIR_Pct_AirHtwPwrTgt_write_IRV: accessed-variable=VeTRIR_Pct_AirHtwPwrTgt_write_IRV
            access WV_VeTRIR_b_AirHtwPwrTgtFA_write_IRV: accessed-variable=VeTRIR_b_AirHtwPwrTgtFA_write_IRV
        PokeTRIR_T_HV_BatClntTmp2_In  # Battery Temperature Inlet Sensor 2 (BTIS2) Poke function
          written-local-variables:
            access WV_VeTRIR_T_HV_BatClntTmp2_In_write_IRV: accessed-variable=VeTRIR_T_HV_BatClntTmp2_In_write_IRV
            access WV_VeTRIR_b_HV_BatClntTmp2_InFA_write_IRV: accessed-variable=VeTRIR_b_HV_BatClntTmp2_InFA_write_IRV
        PokeTRIR_T_HV_BatClntTmp2_Out  # Battery Temperature Outlet Sensor 2 (BTOS2) Poke function
          written-local-variables:
            access WV_VeTRIR_T_HV_BatClntTmp2_Out_write_IRV: accessed-variable=VeTRIR_T_HV_BatClntTmp2_Out_write_IRV
            access WV_VeTRIR_b_HV_BatClntTmp2OutFA_write_IRV: accessed-variable=VeTRIR_b_HV_BatClntTmp2OutFA_write_IRV
        PokeTRIR_T_HV_BatClntTmp_In: variation-point={short-label=vpPokeTRIR_T_HV_BatClntTmp_In, sw-syscond=1}  # Battery Temperature Inlet Sensor (BTIS) Poke function
          written-local-variables:
            access WV_VeTRIR_T_HV_BatClntTmp_In_write_IRV: accessed-variable=VeTRIR_T_HV_BatClntTmp_In_write_IRV, variation-point={short-label=vpWV_VeTRIR_T_HV_BatClntTmp_In_write_IRV, sw-syscond=1}
            access WV_VeTRIR_b_HV_BatClntTmp_InFA_write_IRV: accessed-variable=VeTRIR_b_HV_BatClntTmp_InFA_write_IRV, variation-point={short-label=vpWV_VeTRIR_b_HV_BatClntTmp_InFA_write_IRV, sw-syscond=1}
        PokeTRIR_T_HV_BatClntTmp_Out: variation-point={short-label=vpPokeTRIR_T_HV_BatClntTmp_Out, sw-syscond=1}  # Battery Temperature Outlet Sensor (BTOS) Poke function
          written-local-variables:
            access WV_VeTRIR_T_HV_BatClntTmp_Out_write_IRV: accessed-variable=VeTRIR_T_HV_BatClntTmp_Out_write_IRV, variation-point={short-label=vpWV_VeTRIR_T_HV_BatClntTmp_Out_write_IRV, sw-syscond=1}
            access WV_VeTRIR_b_HV_BatClntTmpOutFA_write_IRV: accessed-variable=VeTRIR_b_HV_BatClntTmpOutFA_write_IRV, variation-point={short-label=vpWV_VeTRIR_b_HV_BatClntTmpOutFA_write_IRV, sw-syscond=1}
        PokeTRIR_T_HeatExCool_TmpOut  # Heat Exchanger Coolant Temperature Outlet Sensor (HXCTOS) Poke function
          written-local-variables:
            access WV_VeTRIR_T_HeatExCool_TmpOut_write_IRV: accessed-variable=VeTRIR_T_HeatExCool_TmpOut_write_IRV
            access WV_VeTRIR_b_HeatExCool_TmpOutFA_write_IRV: accessed-variable=VeTRIR_b_HeatExCool_TmpOutFA_write_IRV
        PokeTRIR_T_HtmpRadCool_TmpIn  # High temperature Radiator Coolant Temperature Inlet Sensor (HRCTIS) Poke function
          written-local-variables:
            access WV_VeTRIR_T_HtmpRadCool_TmpIn_write_IRV: accessed-variable=VeTRIR_T_HtmpRadCool_TmpIn_write_IRV
            access WV_VeTRIR_b_HtmpRadCool_TmpInFA_write_IRV: accessed-variable=VeTRIR_b_HtmpRadCool_TmpInFA_write_IRV
        PokeTRIR_T_HtmpRadCool_TmpOut  # High temperature Radiator Coolant Temperature Outlet Sensor (HRCTOS) Poke function
          written-local-variables:
            access WV_VeTRIR_T_HtmpRadCool_TmpOut_write_IRV: accessed-variable=VeTRIR_T_HtmpRadCool_TmpOut_write_IRV
            access WV_VeTRIR_b_HtmpRadCool_TmpOutFA_write_IRV: accessed-variable=VeTRIR_b_HtmpRadCool_TmpOutFA_write_IRV
        PokeTRIR_T_HtrCorClnt_TmpOut  # Heater Core Coolant Temperature Outlet Sensor (HCCTOS) Poke function
          written-local-variables:
            access WV_VeTRIR_T_HtrCorClnt_TmpOut_write_IRV: accessed-variable=VeTRIR_T_HtrCorClnt_TmpOut_write_IRV
            access WV_VeTRIR_b_HtrCorClnt_TmpOutFA_write_IRV: accessed-variable=VeTRIR_b_HtrCorClnt_TmpOutFA_write_IRV
        PokeTRIR_T_SDS_ClntTmpIn_Act
          written-local-variables:
            access WV_VeTRIR_T_SDS_ClntTmpIn_Act_write_IRV: accessed-variable=VeTRIR_T_SDS_ClntTmpIn_Act_write_IRV
            access WV_VeTRIR_b_SDS_ClntTmpIn_ActFA_write_IRV: accessed-variable=VeTRIR_b_SDS_ClntTmpIn_ActFA_write_IRV
            access WV_VeTRIR_b_SDS_ClntTmpIn_ActSgnl_Rcvd_write_IRV: accessed-variable=VeTRIR_b_SDS_ClntTmpIn_ActSgnl_Rcvd_write_IRV
        PokeTRIR_T_SDS_ClntTmpIn_Tgt
          written-local-variables:
            access WV_VeTRIR_T_SDS_ClntTmpIn_Tgt_write_IRV: accessed-variable=VeTRIR_T_SDS_ClntTmpIn_Tgt_write_IRV
            access WV_VeTRIR_b_SDS_ClntTmpIn_TgtFA_write_IRV: accessed-variable=VeTRIR_b_SDS_ClntTmpIn_TgtFA_write_IRV
            access WV_VeTRIR_b_SDS_ClntTmpIn_TgtSgnl_Rcvd_write_IRV: accessed-variable=VeTRIR_b_SDS_ClntTmpIn_TgtSgnl_Rcvd_write_IRV
        PokeTRIR_b_AHP_EnblReq  # Auxiliary Heater Pump (AHP) enable request Poke function
          written-local-variables:
            access WV_VeTRIR_b_AHP_EnblReqFA_write_IRV: accessed-variable=VeTRIR_b_AHP_EnblReqFA_write_IRV
            access WV_VeTRIR_b_AHP_EnblReq_write_IRV: accessed-variable=VeTRIR_b_AHP_EnblReq_write_IRV
        PokeTRIR_b_BCM_Comfort_EnblAct  # Accessory delay activation Poke function
          written-local-variables:
            access WV_VeTRIR_b_BCM_Comfort_EnblAct_write_IRV: accessed-variable=VeTRIR_b_BCM_Comfort_EnblAct_write_IRV
        PokeTRIR_b_ETM_KeepHotColdButtonStatus  # Keep car hot/cold request - button status Poke function
          written-local-variables:
            access WV_VeTRIR_b_ETM_KeepHotColdButtonStatus_write_IRV: accessed-variable=VeTRIR_b_ETM_KeepHotColdButtonStatus_write_IRV
        PokeTRIR_b_FL_HS_Fail: variation-point={short-label=vpPokeTRIR_b_FL_HS_Fail, sw-syscond=1}  # Front Left Heated Seat fail status Poke function
          written-local-variables:
            access WV_VeTRIR_b_FL_HS_Fail_write_IRV: accessed-variable=VeTRIR_b_FL_HS_Fail_write_IRV, variation-point={short-label=vpWV_VeTRIR_b_FL_HS_Fail_write_IRV, sw-syscond=1}
        PokeTRIR_b_FL_VS_Fail: variation-point={short-label=vpPokeTRIR_b_FL_VS_Fail, sw-syscond=1}  # Front Left Vented Seat fail status Poke function
          written-local-variables:
            access WV_VeTRIR_b_FL_VS_Fail_write_IRV: accessed-variable=VeTRIR_b_FL_VS_Fail_write_IRV, variation-point={short-label=vpWV_VeTRIR_b_FL_VS_Fail_write_IRV, sw-syscond=1}
        PokeTRIR_b_FR_HS_Fail: variation-point={short-label=vpPokeTRIR_b_FR_HS_Fail, sw-syscond=1}  # Front Right Heated Seat fail status Poke function
          written-local-variables:
            access WV_VeTRIR_b_FR_HS_Fail_write_IRV: accessed-variable=VeTRIR_b_FR_HS_Fail_write_IRV, variation-point={short-label=vpWV_VeTRIR_b_FR_HS_Fail_write_IRV, sw-syscond=1}
        PokeTRIR_b_FR_VS_Fail: variation-point={short-label=vpPokeTRIR_b_FR_VS_Fail, sw-syscond=1}  # Front Right Vented Seat fail status Poke function
          written-local-variables:
            access WV_VeTRIR_b_FR_VS_Fail_write_IRV: accessed-variable=VeTRIR_b_FR_VS_Fail_write_IRV, variation-point={short-label=vpWV_VeTRIR_b_FR_VS_Fail_write_IRV, sw-syscond=1}
        PokeTRIR_b_HSW_Fail: variation-point={short-label=vpPokeTRIR_b_HSW_Fail, sw-syscond=1}  # Heated Steering Wheel fail status Poke function
          written-local-variables:
            access WV_VeTRIR_b_HSW_Fail_write_IRV: accessed-variable=VeTRIR_b_HSW_Fail_write_IRV, variation-point={short-label=vpWV_VeTRIR_b_HSW_Fail_write_IRV, sw-syscond=1}
        PokeTRIR_b_LoadShed  # 14V Powernet load shedding status Poke function
          written-local-variables:
            access WV_VeTRIR_b_LoadShed_write_IRV: accessed-variable=VeTRIR_b_LoadShed_write_IRV
        PokeTRIR_b_RL_HS_Fail: variation-point={short-label=vpPokeTRIR_b_RL_HS_Fail, sw-syscond=1}  # Rear Left Heated Seat fail status Poke function
          written-local-variables:
            access WV_VeTRIR_b_RL_HS_Fail_write_IRV: accessed-variable=VeTRIR_b_RL_HS_Fail_write_IRV, variation-point={short-label=vpWV_VeTRIR_b_RL_HS_Fail_write_IRV, sw-syscond=1}
        PokeTRIR_b_RL_VS_Fail: variation-point={short-label=vpPokeTRIR_b_RL_VS_Fail, sw-syscond=1}  # Rear Left Vented Seat fail status Poke function
          written-local-variables:
            access WV_VeTRIR_b_RL_VS_Fail_write_IRV: accessed-variable=VeTRIR_b_RL_VS_Fail_write_IRV, variation-point={short-label=vpWV_VeTRIR_b_RL_VS_Fail_write_IRV, sw-syscond=1}
        PokeTRIR_b_RR_HS_Fail: variation-point={short-label=vpPokeTRIR_b_RR_HS_Fail, sw-syscond=1}  # Rear Right Heated Seat fail status Poke function
          written-local-variables:
            access WV_VeTRIR_b_RR_HS_Fail_write_IRV: accessed-variable=VeTRIR_b_RR_HS_Fail_write_IRV, variation-point={short-label=vpWV_VeTRIR_b_RR_HS_Fail_write_IRV, sw-syscond=1}
        PokeTRIR_b_RR_VS_Fail: variation-point={short-label=vpPokeTRIR_b_RR_VS_Fail, sw-syscond=1}  # Rear Right Vented Seat fail status Poke function
          written-local-variables:
            access WV_VeTRIR_b_RR_VS_Fail_write_IRV: accessed-variable=VeTRIR_b_RR_VS_Fail_write_IRV, variation-point={short-label=vpWV_VeTRIR_b_RR_VS_Fail_write_IRV, sw-syscond=1}
        PokeTRIR_b_SCCActv  # Scheduled Cabin Conditioning (SCC) remote-start Poke function
          written-local-variables:
            access WV_VeTRIR_b_SCCActv_write_IRV: accessed-variable=VeTRIR_b_SCCActv_write_IRV
        PokeTRIR_b_TrunkStatus  # Rear hatch status Poke function
          written-local-variables:
            access WV_VeTRIR_b_TrunkStatus_write_IRV: accessed-variable=VeTRIR_b_TrunkStatus_write_IRV
        PokeTRIR_e_ClimateInfo  # HVAC conditions affecting the Start/Stop functionality Poke function
          written-local-variables:
            access WV_VeTRIR_b_ClimateInfoFA_write_IRV: accessed-variable=VeTRIR_b_ClimateInfoFA_write_IRV
            access WV_VeTRIR_e_ClimateInfo_write_IRV: accessed-variable=VeTRIR_e_ClimateInfo_write_IRV
        PokeTRIR_e_FL_HS_Sts: variation-point={short-label=vpPokeTRIR_e_FL_HS_Sts, sw-syscond=1}  # Front Left Heated Seat status Poke function
          written-local-variables:
            access WV_VeTRIR_e_FL_HS_Sts_write_IRV: accessed-variable=VeTRIR_e_FL_HS_Sts_write_IRV, variation-point={short-label=vpWV_VeTRIR_e_FL_HS_Sts_write_IRV, sw-syscond=1}
        PokeTRIR_e_FL_VS_Sts: variation-point={short-label=vpPokeTRIR_e_FL_VS_Sts, sw-syscond=1}  # Front Left Vented Seat status Poke function
          written-local-variables:
            access WV_VeTRIR_e_FL_VS_Sts_write_IRV: accessed-variable=VeTRIR_e_FL_VS_Sts_write_IRV, variation-point={short-label=vpWV_VeTRIR_e_FL_VS_Sts_write_IRV, sw-syscond=1}
        PokeTRIR_e_FR_HS_Sts: variation-point={short-label=vpPokeTRIR_e_FR_HS_Sts, sw-syscond=1}  # Front Right Heated Seat status Poke function
          written-local-variables:
            access WV_VeTRIR_e_FR_HS_Sts_write_IRV: accessed-variable=VeTRIR_e_FR_HS_Sts_write_IRV, variation-point={short-label=vpWV_VeTRIR_e_FR_HS_Sts_write_IRV, sw-syscond=1}
        PokeTRIR_e_FR_VS_Sts: variation-point={short-label=vpPokeTRIR_e_FR_VS_Sts, sw-syscond=1}  # Front Right Vented Seat status Poke function
          written-local-variables:
            access WV_VeTRIR_e_FR_VS_Sts_write_IRV: accessed-variable=VeTRIR_e_FR_VS_Sts_write_IRV, variation-point={short-label=vpWV_VeTRIR_e_FR_VS_Sts_write_IRV, sw-syscond=1}
        PokeTRIR_e_HSW_Sts: variation-point={short-label=vpPokeTRIR_e_HSW_Sts, sw-syscond=1}  # Heated Steering Wheel status Poke function
          written-local-variables:
            access WV_VeTRIR_b_HSW_StsFA_write_IRV: accessed-variable=VeTRIR_b_HSW_StsFA_write_IRV, variation-point={short-label=vpWV_VeTRIR_b_HSW_StsFA_write_IRV, sw-syscond=1}
            access WV_VeTRIR_e_HSW_Sts_write_IRV: accessed-variable=VeTRIR_e_HSW_Sts_write_IRV, variation-point={short-label=vpWV_VeTRIR_e_HSW_Sts_write_IRV, sw-syscond=1}
        PokeTRIR_e_HVACECOModeSts  # Heating Ventilation Air Conditioning (HVAC) ECO mode status Poke function
          written-local-variables:
            access WV_VeTRIR_b_HVACECOModeStsFA_write_IRV: accessed-variable=VeTRIR_b_HVACECOModeStsFA_write_IRV
            access WV_VeTRIR_e_HVACECOModeSts_write_IRV: accessed-variable=VeTRIR_e_HVACECOModeSts_write_IRV
        PokeTRIR_e_HVACPrecCondSts  # HVAC - cabin preconditioning status Poke function
          written-local-variables:
            access WV_VeTRIR_e_HVACPrecCondSts_write_IRV: accessed-variable=VeTRIR_e_HVACPrecCondSts_write_IRV
        PokeTRIR_e_RL_HS_Sts: variation-point={short-label=vpPokeTRIR_e_RL_HS_Sts, sw-syscond=1}  # Rear Left Heated Seat status Poke function
          written-local-variables:
            access WV_VeTRIR_e_RL_HS_Sts_write_IRV: accessed-variable=VeTRIR_e_RL_HS_Sts_write_IRV, variation-point={short-label=vpWV_VeTRIR_e_RL_HS_Sts_write_IRV, sw-syscond=1}
        PokeTRIR_e_RL_VS_Sts: variation-point={short-label=vpPokeTRIR_e_RL_VS_Sts, sw-syscond=1}  # Rear Left Vented Seat status Poke function
          written-local-variables:
            access WV_VeTRIR_e_RL_VS_Sts_write_IRV: accessed-variable=VeTRIR_e_RL_VS_Sts_write_IRV, variation-point={short-label=vpWV_VeTRIR_e_RL_VS_Sts_write_IRV, sw-syscond=1}
        PokeTRIR_e_RR_HS_Sts: variation-point={short-label=vpPokeTRIR_e_RR_HS_Sts, sw-syscond=1}  # Rear Right Heated Seat status Poke function
          written-local-variables:
            access WV_VeTRIR_e_RR_HS_Sts_write_IRV: accessed-variable=VeTRIR_e_RR_HS_Sts_write_IRV, variation-point={short-label=vpWV_VeTRIR_e_RR_HS_Sts_write_IRV, sw-syscond=1}
        PokeTRIR_e_RR_VS_Sts: variation-point={short-label=vpPokeTRIR_e_RR_VS_Sts, sw-syscond=1}  # Rear Right Vented Seat status Poke function
          written-local-variables:
            access WV_VeTRIR_e_RR_VS_Sts_write_IRV: accessed-variable=VeTRIR_e_RR_VS_Sts_write_IRV, variation-point={short-label=vpWV_VeTRIR_e_RR_VS_Sts_write_IRV, sw-syscond=1}
        PokeTRIR_e_SDS_ActualState
          written-local-variables:
            access WV_VeTRIR_b_SDS_ActualStateFA_write_IRV: accessed-variable=VeTRIR_b_SDS_ActualStateFA_write_IRV
            access WV_VeTRIR_b_SDS_ActualStateSgnl_Rcvd_write_IRV: accessed-variable=VeTRIR_b_SDS_ActualStateSgnl_Rcvd_write_IRV
            access WV_VeTRIR_e_SDS_ActualState_write_IRV: accessed-variable=VeTRIR_e_SDS_ActualState_write_IRV
        PokeTRIR_e_SDS_MaxCoolingReq
          written-local-variables:
            access WV_VeTRIR_b_SDS_MaxCoolingReqFA_write_IRV: accessed-variable=VeTRIR_b_SDS_MaxCoolingReqFA_write_IRV
            access WV_VeTRIR_b_SDS_MaxCoolingReqSgnl_Rcvd_write_IRV: accessed-variable=VeTRIR_b_SDS_MaxCoolingReqSgnl_Rcvd_write_IRV
            access WV_VeTRIR_e_SDS_MaxCoolingReq_write_IRV: accessed-variable=VeTRIR_e_SDS_MaxCoolingReq_write_IRV
        TmotTRIR_T_SDS_ClntTmpIn_Act
          written-local-variables:
            access WV_VeTRIR_b_SDS_ClntTmpIn_ActSgnl_Rcvd_write_IRV: accessed-variable=VeTRIR_b_SDS_ClntTmpIn_ActSgnl_Rcvd_write_IRV
        TmotTRIR_b_HVACPrecCondSts  # HVAC - cabin preconditioning status Timeout function
        TmotTRIR_b_SCCActv  # Scheduled Cabin Conditioning (SCC) remote-start Timeout function
      variation point proxy Variant_TRIR_1: category=CONDITION, condition-access=0
      variation point proxy Variant_TRIR_2: category=CONDITION, condition-access=0
      variation point proxy Variant_TRIR_3: category=CONDITION, condition-access=1
